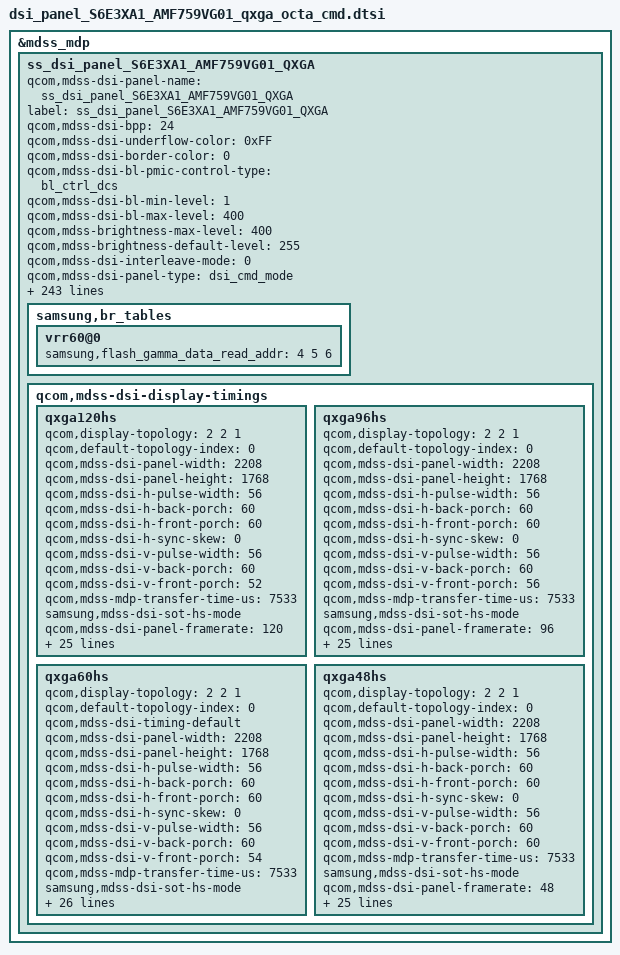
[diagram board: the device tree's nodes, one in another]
/* Copyright (c) 2012, Samsung Electronics Corporation. All rights reserved.
 *
 * This program is free software; you can redistribute it and/or modify
 * it under the terms of the GNU General Public License version 2 and
 * only version 2 as published by the Free Software Foundation.
 *
 * This program is distributed in the hope that it will be useful,
 * but WITHOUT ANY WARRANTY; without even the implied warranty of
 * MERCHANTABILITY or FITNESS FOR A PARTICULAR PURPOSE.  See the
 * GNU General Public License for more details.
 */

&mdss_mdp {
	ss_dsi_panel_S6E3XA1_AMF759VG01_QXGA: ss_dsi_panel_S6E3XA1_AMF759VG01_QXGA {
		qcom,mdss-dsi-panel-name = "ss_dsi_panel_S6E3XA1_AMF759VG01_QXGA";
		label = "ss_dsi_panel_S6E3XA1_AMF759VG01_QXGA";

		qcom,mdss-dsi-bpp = <24>;

		qcom,mdss-dsi-underflow-color = <0xFF>;
		qcom,mdss-dsi-border-color = <0>;

		qcom,mdss-dsi-bl-pmic-control-type = "bl_ctrl_dcs";

		qcom,mdss-dsi-bl-min-level = <1>;
		qcom,mdss-dsi-bl-max-level = <400>;
		qcom,mdss-brightness-max-level = <400>;
		qcom,mdss-brightness-default-level = <255>;
		qcom,mdss-dsi-interleave-mode = <0>;
		qcom,mdss-dsi-panel-type = "dsi_cmd_mode";

		qcom,mdss-dsi-te-pin-select = <1>;

		qcom,dynamic-mode-switch-enabled;
		qcom,dynamic-mode-switch-type = "dynamic-resolution-switch-immediate";

		qcom,mdss-dsi-te-dcs-command = <1>;
		qcom,mdss-dsi-wr-mem-start = <0x2C>;
		qcom,mdss-dsi-wr-mem-continue = <0x3C>;

		qcom,mdss-dsi-pixel-packing = "loose";

		qcom,mdss-dsi-virtual-channel-id = <0>;
		qcom,mdss-dsi-color-order = "rgb_swap_rgb";
		qcom,mdss-dsi-lane-0-state;
		qcom,mdss-dsi-lane-1-state;
		qcom,mdss-dsi-lane-2-state;
		qcom,mdss-dsi-lane-3-state;

		qcom,mdss-dsi-t-clk-pre = <0x24>;
		qcom,mdss-dsi-t-clk-post = <0x1b>;

		qcom,mdss-dsi-mdp-trigger = "none";
		qcom,mdss-dsi-dma-trigger = "trigger_sw";

		qcom,mdss-pan-physical-height-dimension = <120>; /* 120.472 */
		qcom,mdss-pan-physical-width-dimension = <150>; /* 150.453 */

		qcom,mdss-dsi-reset-sequence = <0 1>, <1 5>;

		/*qcom,mdss-dsi-lp11-init;*/
		/*qcom,mdss-dsi-init-delay-us = <1000>;*/

		qcom,mdss-dsi-rx-eot-ignore;
		qcom,mdss-dsi-tx-eot-append;

		/* HDR Setting */
		qcom,mdss-dsi-panel-hdr-enabled;
		qcom,mdss-dsi-panel-hdr-color-primaries = <15635 16450 34000 16000 13250 34500 7500 3000>;
		qcom,mdss-dsi-panel-peak-brightness = <4000000>;
		qcom,mdss-dsi-panel-average-brightness = <1200000>;
		qcom,mdss-dsi-panel-blackness-level = <5>;

		qcom,ulps-enabled;
		/* qcom,suspend-ulps-enabled; */
		qcom,esd-check-enabled;
		qcom,mdss-dsi-panel-status-check-mode ="irq_check";
		/*qcom,mdss-dsi-panel-status-read-length;*/
		/*qcom,mdss-dsi-panel-status-value;*/
		/*qcom,mdss-dsi-panel-status-irq-trigger1 = "rising";*/
		//qcom,mdss-dsi-panel-status-irq-trigger1 = "falling";

		/* *************************************************************
		 * Below  parameters are samsung dependent thigs
		 * *************************************************************
		 */
		samsung,panel-vendor = "SDC";
		samsung,disp-model = "AMF759VG01";
		samsung,panel-lpm-enable;
		samsung,support_irc;
		samsung,elvss_interpolation_temperature = <(-15)>;
		samsung,support_factory_panel_swap;
		samsung,support_gct;
		samsung,esc-clk-128M;
		samsung,support_gamma_mode2;
		samsung,support_gpara;

		/* *************************************************************
		 * TEST MODE
		 * **************************************************************
		 */


		/***************************** 60 NM *****************************/
		/* MCD Test : 60hz Normal mode */
		samsung,mcd_on_tx_cmds_revA = [
			29 00 00 00 00 00 03 F0 5A 5A	/* TEST KEY2 Enable */
			29 01 00 00 00 00 EC CB			/* LTPS Setting */
				00 25 1D 1D 00 00 00 00 00 DF 4F DD E5 D2 E3 9A
				90 D9 D0 C7 D0 C2 D0 88 D0 C3 50 DF CF DD E5 D2
				E3 9A 90 D9 D0 87 D0 82 D0 C8 D0 C3 D0 80 C0 00
				00 00 00 00 00 00 00 00 00 00 00 00 00 00 00 00
				00 00 00 00 00 00 04 00 06 00 00 00 0B 00 02 00
				06 02 00 00 00 00 00 00 00 00 00 00 00 00 50 2E
				1A 00 00 00 40 2E 1A 00 00 00 00 00 00 00 00 00
				00 00 00 00 00 00 00 00 00 00 00 00 04 00 00 00
				00 00 33 00 00 00 00 00 00 50 04 37 40 04 37 00
				00 00 00 00 00 F8 04 37 00 00 00 D8 04 37 00 00
				00 00 00 00 00 00 00 12 00 00 00 00 00 00 00 00
				04 00 06 00 00 00 0B 00 02 00 06 02 00 00 00 00
				00 00 00 00 00 00 00 00 50 0B 35 00 00 00 40 0B
				35 00 00 00 00 00 00 00 00 00 00 00 00 00 00 00
				00 00 00 00 00 00 04 00 00 00 00
			29 00 00 00 00 00 03 B0 13 F6
			29 00 00 00 00 00 02 F6 00
			29 01 00 00 64 00 02 F7 0F	/* gamma update, delay 100ms */
			29 01 00 00 00 00 03 F0 A5 A5	/* TEST KEY2 Disable */
		];

		samsung,mcd_off_tx_cmds_revA = [
			29 00 00 00 00 00 03 F0 5A 5A	/* TEST KEY2 Enable */
			29 01 00 00 00 00 EC CB			/* LTPS Setting */
				00 25 1D 1D 00 00 00 00 00 DF 0F DD E5 D2 E3 9A
				90 D9 D0 C7 D0 C2 D0 88 D0 C3 50 DF CF DD E5 D2
				E3 9A 90 D9 D0 87 D0 82 D0 C8 D0 C3 D0 80 C0 00
				00 00 00 00 00 00 00 00 00 00 00 00 00 00 00 00
				00 00 00 00 00 00 04 00 06 00 00 00 0B 00 02 00
				06 02 00 00 00 00 00 00 00 00 00 00 00 00 50 2E
				1A 00 00 00 40 2E 1A 00 00 00 00 00 00 00 00 00
				00 00 00 00 00 00 00 00 00 00 00 00 04 00 00 00
				00 00 33 00 00 00 00 00 00 50 04 37 40 04 37 00
				00 00 00 00 00 F8 04 37 00 00 00 D8 04 37 00 00
				00 00 00 00 00 00 00 00 00 00 00 00 00 00 00 00
				04 00 06 00 00 00 0B 00 02 00 06 02 00 00 00 00
				00 00 00 00 00 00 00 00 50 0B 35 00 00 00 40 0B
				35 00 00 00 00 00 00 00 00 00 00 00 00 00 00 00
				00 00 00 00 00 00 04 00 00 00 00
			29 00 00 00 00 00 03 B0 13 F6
			29 00 00 00 00 00 02 F6 46
			29 00 00 00 64 00 02 F7 0F	/* gamma update, delay 100ms */
			29 01 00 00 00 00 03 F0 A5 A5	/* TEST KEY2 Disable */
		];
		/* MCD Test : 120hz Normal mode */
		samsung,mcd_on_tx_cmds_revC = [
			29 00 00 00 00 00 03 F0 5A 5A	/* TEST KEY2 Enable */
			29 00 00 00 00 00 03 FC 5A 5A	/* TEST KEY1 Enable */
			29 00 00 00 00 00 02 C5 08		/* FFC Disable */
			29 00 00 00 00 00 02 BD 00		/* LFD Disable */
			29 00 00 00 00 00 03 B0 23 F6
			29 00 00 00 00 00 02 F6 24
			29 01 00 00 00 00 EC CB			/* LTPS Setting */
				00 25 1D 1D 00 00 00 00 00 DF 0F DD E5 D2 E3 9A
				90 D9 D0 C7 D0 C2 D0 88 D0 C3 50 DF CF DD E5 D2
				E3 9A 90 D9 D0 87 D0 82 D0 C8 D0 C3 D0 80 C0 00
				00 00 00 00 00 00 00 00 00 00 00 00 00 00 00 00
				00 00 00 00 00 00 04 00 08 00 00 00 0F 00 02 00
				00 00 00 00 00 00 00 00 00 00 00 00 00 00 50 2E
				1A 00 00 00 40 2E 1A 00 00 00 00 00 00 00 00 00
				00 00 00 00 00 00 00 00 00 00 00 00 04 00 00 00
				00 00 33 00 00 00 00 00 00 50 04 37 40 04 37 00
				00 00 00 00 00 F8 04 37 00 00 00 D8 04 37 00 00
				00 00 00 00 00 00 00 04 00 00 00 00 00 00 00 00
				04 00 08 00 00 00 0F 00 02 00 00 00 00 00 00 00
				00 00 00 00 00 00 00 00 50 5C 35 00 00 00 40 5C
				35 00 00 00 00 00 00 00 00 00 00 00 00 00 00 00
				00 00 00 00 00 00 04 00 00 00 00
			29 01 00 00 00 00 E4 B7			/* LTPS Setting */
				00 33 00 00 00 00 00 00 50 09 6E 40 09 6E 00 00
				00 00 00 00 F8 09 6E 00 00 00 D8 09 6E 00 00 00
				00 00 00 00 00 00 24 00 00 00 00 00 00 00 00 04
				00 08 00 00 00 0F 00 02 00 00 00 00 00 00 00 00
				00 00 00 00 00 00 00 50 40 0D 00 00 00 40 40 0D
				00 00 00 00 00 00 00 00 00 00 00 00 00 00 00 00
				00 00 00 00 00 04 00 00 00 00 00 33 00 00 00 00
				00 00 50 02 44 40 02 44 00 00 00 00 00 00 F8 02
				44 00 00 00 D8 02 44 00 00 00 00 00 00 00 00 00
				10 00 00 00 00 00 00 00 00 00 00 00 00 00 00 00
				00 00 00 00 00 00 00 00 00 00 00 00 00 00 00 00
				00 00 00 00 00 00 00 00 00 00 00 00 00 00 00 00
				00 00 00 00 00 00 00 00 00 00 00 00 00 00 00 00
				00 00 00 00 00 00 00 00 00 00 00 00 00 00 00 00
				00 00 00
			29 00 00 00 00 00 03 B0 08 F2
			29 00 00 00 00 00 03 F2 28 50
			29 00 00 00 00 00 03 B0 0F F2
			29 00 00 00 00 00 03 F2 28 50
			29 00 00 00 00 00 03 B0 17 F6
			29 00 00 00 00 00 02 F6 00
			29 01 00 00 64 00 02 F7 0F	/* gamma update, delay 100ms */
			29 00 00 00 00 00 03 FC A5 A5	/* TEST KEY1 Disable */
			29 01 00 00 00 00 03 F0 A5 A5	/* TEST KEY2 Disable */
		];

		samsung,mcd_off_tx_cmds_revC = [
			29 00 00 00 00 00 03 F0 5A 5A	/* TEST KEY2 Enable */
			29 00 00 00 00 00 03 FC 5A 5A	/* TEST KEY1 Enable */
			29 00 00 00 00 00 02 C5 0D		/* FFC Disable */
			29 00 00 00 00 00 03 B0 23 F6
			29 00 00 00 00 00 02 F6 00
			29 01 00 00 00 00 EC CB			/* LTPS Setting */
				00 25 1D 1D 00 00 00 00 00 DF 0F DD E5 D2 E3 9A
				90 D9 D0 C7 D0 C2 D0 88 D0 C3 50 DF CF DD E5 D2
				E3 9A 90 D9 D0 87 D0 82 D0 C8 D0 C3 D0 80 C0 00
				00 00 00 00 00 00 00 00 00 00 00 00 00 00 00 00
				00 00 00 00 00 00 04 00 08 00 00 00 0F 00 02 00
				06 02 00 00 00 00 00 00 00 00 00 00 00 00 50 2E
				1A 00 00 00 40 2E 1A 00 00 00 00 00 00 00 00 00
				00 00 00 00 00 00 00 00 00 00 00 00 04 00 00 00
				00 00 1D 00 00 00 00 00 00 50 04 37 40 04 37 00
				00 00 00 00 00 F8 04 37 00 00 00 D8 04 37 00 00
				00 00 00 00 00 00 00 00 00 00 00 00 00 00 00 00
				04 00 08 00 00 00 0F 00 02 00 06 02 00 00 00 00
				00 00 00 00 00 00 00 00 50 0B 35 00 00 00 40 0B
				35 00 00 00 00 00 00 00 00 00 00 00 00 00 00 00
				00 00 00 00 00 00 04 00 00 00 00
			29 01 00 00 00 00 E4 B7			/* LTPS Setting */
				00 1D 00 00 00 00 00 00 50 09 37 40 09 37 00 00
				00 00 00 00 F8 09 2E 00 00 00 D8 09 2E 00 00 00
				00 00 00 00 00 00 00 00 00 00 00 00 00 00 00 04
				00 08 00 00 00 0F 00 02 00 00 00 00 00 00 00 00
				00 00 00 00 00 00 00 50 30 0D 00 00 00 40 30 0D
				00 00 00 00 00 00 00 00 00 00 00 00 00 00 00 00
				00 00 00 00 00 04 00 00 00 00 00 1D 00 00 00 00
				00 00 50 02 44 40 02 44 00 00 00 00 00 00 F8 02
				44 00 00 00 D8 02 44 00 00 00 00 00 00 00 00 00
				00 00 00 00 00 00 00 00 00 00 00 00 00 00 00 00
				00 00 00 00 00 00 00 00 00 00 00 00 00 00 00 00
				00 00 00 00 00 00 00 00 00 00 00 00 00 00 00 00
				00 00 00 00 00 00 00 00 00 00 00 00 00 00 00 00
				00 00 00 00 00 00 00 00 00 00 00 00 00 00 00 00
				00 00 00
			29 00 00 00 00 00 03 B0 08 F2
			29 00 00 00 00 00 03 F2 14 50
			29 00 00 00 00 00 03 B0 0F F2
			29 00 00 00 00 00 03 F2 14 50
			29 00 00 00 00 00 03 B0 17 F6
			29 00 00 00 00 00 02 F6 3D
			29 00 00 00 00 00 02 F7 0F		/* gamma update */
			29 00 00 00 00 00 02 BD 01		/* LFD Enable */
			29 00 00 00 00 00 03 FC A5 A5	/* TEST KEY1 Disable */
			29 01 00 00 00 00 03 F0 A5 A5	/* TEST KEY2 Disable */
		];

		/* BRIGHTDOT Test : 120hz HS mode */
		samsung,brightdot_on_tx_cmds_revA = [
			29 00 00 00 00 00 03 F0 5A 5A	/* TEST KEY2 Enable */
			29 00 00 00 00 00 03 51 03 FF	/* max brightness */
			29 00 00 00 00 00 03 B0 59 B1
			29 00 00 00 00 00 03 B1 07 00	/* AOR 100% */
			29 01 00 00 64 00 02 F7 0F	/* gamma update */
			29 00 00 00 00 00 03 F0 A5 A5	/* TEST KEY2 Disable */
		];

		samsung,brightdot_off_tx_cmds_revA = [
			29 00 00 00 00 00 03 F0 5A 5A	/* TEST KEY2 Enable */
			29 00 00 00 00 00 03 B0 59 B1
			29 00 00 00 00 00 03 B1 01 20	/* AOR 16% (OTP value) */
			29 01 00 00 64 00 02 F7 0F	/* gamma update */
			29 00 00 00 00 00 03 F0 A5 A5	/* TEST KEY2 Disable */
		];

		samsung,brightdot_lf_on_tx_cmds_revA = [
			29 00 00 00 00 00 03 F0 5A 5A	/* TEST KEY2 Enable */
			29 00 00 00 00 00 03 51 03 FF	/* max brightness */
			29 00 00 00 00 00 03 B0 0C BD
			29 00 00 00 00 00 03 BD 00 EF	/* LFD min freq. = 0.5hz on 120HS mdoe */
			29 00 00 00 00 00 03 60 00 EF	/* LFD max freq. = 0.5hz on 120HS mdoe */
			29 01 00 00 64 00 02 F7 0F	/* gamma update */
			29 00 00 00 00 00 03 F0 A5 A5	/* TEST KEY2 Disable */
		];

		/* samsung,brightdot_lf_off_tx_cmds_revA = []; by updating brightness, LFD will be recovered */

		/* Gray Spot Test : 120Hz HS mode */
		samsung,gray_spot_test_on_tx_cmds_revA = [
			29 00 00 00 00 00 03 F0 5A 5A	/* TEST KEY2 Enable */
			29 00 00 00 00 00 02 BD 00		/* LFD Disable */
			29 00 00 00 00 00 03 B0 02 B5
			29 00 00 00 00 00 02 B5 23
			29 00 00 00 00 00 03 B0 4A B5
			29 00 00 00 00 00 02 B5 12
			29 01 00 00 14 00 02 F7 0F	/* gamma update delay 20ms*/
			29 00 00 00 00 00 03 B0 17 F6
			29 00 00 00 00 00 02 F6 00
			29 00 00 00 00 00 03 B0 01 F2
			29 00 00 00 00 00 04 F2 00 BA 00
			29 00 00 00 00 00 02 F7 0F	/* gamma update */
			29 01 00 00 00 00 03 F0 A5 A5	/* TEST KEY2 Disable */
		];

		samsung,gray_spot_test_off_tx_cmds_revA = [
			29 00 00 00 00 00 03 F0 5A 5A	/* TEST KEY2 Enable */
			29 00 00 00 00 00 03 B0 17 F6
			29 00 00 00 00 00 02 F6 3D
			29 00 00 00 00 00 03 B0 01 F2
			29 00 00 00 00 00 04 F2 14 BA 40
			29 00 00 00 00 00 03 B0 02 B5
			29 00 00 00 00 00 02 B5 16
			29 00 00 00 00 00 03 B0 4A B5
			29 00 00 00 00 00 02 B5 00
			29 00 00 00 00 00 02 BD 01		/* LFD Enable */
			29 00 00 00 00 00 02 F7 0F	/* gamma update */
			29 01 00 00 00 00 03 F0 A5 A5	/* TEST KEY2 Disable */
		];

		samsung,gray_spot_rx_cmds_revA= [06 01 00 00 00 00 01 B5 01 74];

		/* Micro Crack Test 120Hz HS*/
		samsung,micro_short_test_on_tx_cmds_revA = [
			29 00 00 00 00 00 03 F0 5A 5A
			29 00 00 00 00 00 03 B0 17 F6
			29 00 00 00 00 00 02 F6 2B
			29 00 00 00 00 00 03 BF 33 25
			29 01 00 00 00 00 03 F0 A5 A5
		];

		samsung,micro_short_test_off_tx_cmds_revA = [
			29 00 00 00 00 00 03 F0 5A 5A
			29 00 00 00 00 00 03 B0 17 F6
			29 00 00 00 00 00 02 F6 3D
			29 00 00 00 00 00 03 BF 00 07
			29 01 00 00 00 00 03 F0 A5 A5
		];

		samsung,ccd_test_on_tx_cmds_revA = [
			29 00 00 00 00 00 03 F0 5A 5A
			29 00 00 00 00 00 03 B0 02 CC
			29 01 00 00 00 00 02 CC 01
			29 00 00 00 00 00 03 F0 A5 A5
		];

		samsung,ccd_state_rx_cmds_revA= [06 01 00 00 00 00 01 CD 01 00];

		samsung,ccd_pass_val = <0x00>;	/* pass */
		samsung,ccd_fail_val = <0x04>;	/* chip crack */

		samsung,ccd_test_off_tx_cmds_revA = [
			29 00 00 00 00 00 03 F0 5A 5A
			29 00 00 00 00 00 03 B0 02 CC			
			29 00 00 00 00 00 02 CC 00
			29 01 00 00 00 00 03 F0 A5 A5
		];

		samsung,gct_checksum_rx_cmds_revA = [06 01 00 00 00 00 01 AF 01 00];

		samsung,gct_enter_tx_cmds_revA = [
			29 00 00 00 00 00 03 9F A5 A5	// TEST KEY Enable
			05 01 00 00 78 00 01 01		// S/W Reset, Delay 120ms

			29 00 00 00 00 00 03 F0 5A 5A	// TEST KEY Enable
			29 00 00 00 00 00 03 FC 5A 5A	// TEST KEY Enable

			29 00 00 00 00 00 03 B0 0A FE	// Global Para

			29 00 00 00 00 00 02 FE 14	// Para

			29 00 00 00 00 00 5A 9E		/* PPS */
				11 00 00 89 30 80 06 E8
				08 A0 00 22 04 50 04 50
				02 00 03 28 00 20 04 6C
				00 0F 00 0C 02 E9 01 77
				18 00 10 F0 03 0C 20 00
				06 0B 0B 33 0E 1C 2A 38
				46 54 62 69 70 77 79 7B
				7D 7E 01 02 01 00 09 40
				09 BE 19 FC 19 FA 19 F8
				1A 38 1A 78 1A B6 2A F6
				2B 34 2B 74 3B 74 6B F4
				00

			05 01 00 00 0A 00 01 11		// Sleep out, Delay 10ms

			29 00 00 00 00 00 03 B0 2D FE
			29 01 00 00 32 00 02 FE 7A
			29 00 00 00 00 00 03 51 03 FF
			29 01 00 00 00 00 02 53 20
			29 01 00 00 00 00 02 9D 01		/* DSC enable */
			29 01 00 00 32 00 02 D7 04		/* LDDM LV Setting */
			29 01 00 00 00 00 02 2C 00		/* Checksum start */

			29 01 00 00 14 00 02 BE 05		/* GDBIST Pattern 5A , delay 20ms */
			29 01 00 00 14 00 02 BE 00		/* GDBIST Disable, delay 20ms */
			29 00 00 00 00 00 02 BE 07		/* GDBIST Pattern A5 , delay 150ms(panel file) */

			/* checksum read */
		];

		samsung,gct_mid_tx_cmds_revA = [
			29 01 00 00 14 00 02 BE 00		// GDBIST Disable, delay 20ms
			29 00 00 00 00 00 02 BE 05		// GDBIST Pattern 2 , delay 150ms(panel file)

			/* checksum read */
		];

		samsung,gct_exit_tx_cmds_revA = [
			29 00 00 00 00 00 02 BE 00		// GDBIST Disable
			29 00 00 00 00 00 02 D7 00		// VDDM Normal Setting (VDDM 0x0: 1.0V, 0x10: 0.9V, 0x30: 1.1V)
			29 00 00 00 00 00 03 9F 5A 5A	// TEST Key Disable
			29 00 00 00 00 00 03 F0 A5 A5	// TEST Key Disable
			29 01 00 00 00 00 03 FC A5 A5	// TEST Key Disable
		];

		/* *************************************************************
		 *  SELF DISPLAY
		 * *************************************************************
		 */
		samsung,support_self_display;
		ss,self_display = <&self_display_XA1_dtsi>;


		/* Self idle-Display Operation (Enable/Disable) */
		samsung,self_idle_aod_enter = [
			29 00 00 00 00 00 03 FC 5A 5A	/* TEST KEY Enable */
			29 00 00 00 00 00 05 76 13 0C 00 11
			29 00 00 00 00 00 03 FC A5 A5	/* TEST KEY Disable */
		];

		samsung,self_idle_aod_exit = [
			29 00 00 00 00 00 03 FC 5A 5A	/* TEST KEY Enable */
			29 00 00 00 00 00 05 76 13 0C 00 00
			29 00 00 00 00 00 02 75 01
			29 00 00 00 00 00 03 FC A5 A5	/* TEST KEY Disable */
		];

		/* Self idle-Display Operation (SELF TIME UPDATE) */
		samsung,self_idle_timer_on = [
			29 00 00 00 00 00 03 F0 5A 5A	/* TEST KEY Enable */
			29 00 00 00 00 00 0B 81
								00 03 00 00 00
								00 03 00 00 00
			29 00 00 00 00 00 03 F0 A5 A5	/* TEST KEY Disable */
		];

		samsung,self_idle_timer_off = [
			29 00 00 00 00 00 03 F0 5A 5A	/* TEST KEY Enable */
			29 00 00 00 00 00 03 81 00 00
			29 01 00 00 11 00 03 F0 A5 A5	/* TEST KEY Disable + Delay 16.7 ms*/
		];

		/* Self idle-Display Operation (SELF MOVE) */

		samsung,self_idle_move_on_pattern1 = [
			29 00 00 00 00 00 03 F0 5A 5A	/* TEST KEY Enable */
			29 00 00 00 00 00 23 7D
						10 01 02 00 00
						10 01 50 05 10 01 50 05
						10 01 50 05 10 01 50 05
						10 01 00 00 00 00 00 00
						00 00 00 00 00
			29 00 00 00 00 00 03 F0 A5 A5	/* TEST KEY Disable */
		];

		samsung,self_idle_move_on_pattern2 = [
			29 00 00 00 00 00 03 F0 5A 5A	/* TEST KEY Enable */
			29 00 00 00 00 00 23 7D
						10 01 02 00 00
						10 01 50 05 10 01 50 05
						10 01 50 05 10 01 50 05
						10 01 00 00 00 00 00 00
						00 00 00 00 00
			29 00 00 00 00 00 03 F0 A5 A5	/* TEST KEY Disable */
		];

		samsung,self_idle_move_on_pattern3 = [
			29 00 00 00 00 00 03 F0 5A 5A	/* TEST KEY Enable */
			29 00 00 00 00 00 23 7D
								10 01 02 00 00
								10 01 50 05 10 01 50 05
								10 01 50 05 10 01 50 05
								10 01 00 00 00 00 00 00
								00 00 00 00 00
			29 00 00 00 00 00 03 F0 A5 A5	/* TEST KEY Disable */
		];
		samsung,self_idle_move_on_pattern4 = [
			29 00 00 00 00 00 03 F0 5A 5A	/* TEST KEY Enable */
			29 00 00 00 00 00 23 7D
								10 01 02 00 00
								10 01 50 05 10 01 50 05
								10 01 50 05 10 01 50 05
								10 01 00 00 00 00 00 00
								00 00 00 00 00
			29 00 00 00 00 00 03 F0 A5 A5	/* TEST KEY Disable */
		];
		samsung,self_idle_move_off = [
			29 00 00 00 00 00 03 F0 5A 5A	/* TEST KEY Enable */
			29 00 00 00 00 00 03 7D 00 00
			29 00 00 00 00 00 03 F0 A5 A5	/* TEST KEY Disable */
		];

		/*
		*************************************************************************************************************************
		* Self mask check debug (SELF MASK CHECK)
		*************************************************************************************************************************
		*/

		samsung,mask_crc_pass_data = [2A C3];

		/* *************************************************************
		 *  mAFPC
		 * *************************************************************
		 */
		samsung,support_mafpc;
		ss,mafpc = <&ss_mafpc_XA1_dtsi>;
		samsung,mafpc_crc_pass_data = [62 2D];

		/* *************************************************************
		 *  Tx
		 * *************************************************************
		 */
		samsung,level0_key_enable_tx_cmds_revA	= [29 01 00 00 00 00 03 9F A5 A5]; /* PASSWD0 */
		samsung,level0_key_disable_tx_cmds_revA	= [29 01 00 00 00 00 03 9F 5A 5A]; /* PASSWD0 */
		samsung,level1_key_enable_tx_cmds_revA	= [29 01 00 00 00 00 03 F0 5A 5A]; /* PASSWD1 */
		samsung,level1_key_disable_tx_cmds_revA	= [29 01 00 00 00 00 03 F0 A5 A5]; /* PASSWD1 */
		samsung,level2_key_enable_tx_cmds_revA	= [29 01 00 00 00 00 03 FC 5A 5A];
		samsung,level2_key_disable_tx_cmds_revA	= [29 01 00 00 00 00 03 FC A5 A5];

		/* BRIGHTNESS_MAX_PACKET = 100 */
		samsung,brightness_tx_cmds_revA = [
			39 01 00 00 00 00 01 00
			39 01 00 00 00 00 01 00
			39 01 00 00 00 00 01 00
			39 01 00 00 00 00 01 00
			39 01 00 00 00 00 01 00
			39 01 00 00 00 00 01 00
			39 01 00 00 00 00 01 00
			39 01 00 00 00 00 01 00
			39 01 00 00 00 00 01 00
			39 01 00 00 00 00 01 00
			39 01 00 00 00 00 01 00
			39 01 00 00 00 00 01 00
			39 01 00 00 00 00 01 00
			39 01 00 00 00 00 01 00
			39 01 00 00 00 00 01 00
			39 01 00 00 00 00 01 00
			39 01 00 00 00 00 01 00
			39 01 00 00 00 00 01 00
			39 01 00 00 00 00 01 00
			39 01 00 00 00 00 01 00
			39 01 00 00 00 00 01 00
			39 01 00 00 00 00 01 00
			39 01 00 00 00 00 01 00
			39 01 00 00 00 00 01 00
			39 01 00 00 00 00 01 00
			39 01 00 00 00 00 01 00
			39 01 00 00 00 00 01 00
			39 01 00 00 00 00 01 00
			39 01 00 00 00 00 01 00
			39 01 00 00 00 00 01 00
			39 01 00 00 00 00 01 00
			39 01 00 00 00 00 01 00
			39 01 00 00 00 00 01 00
			39 01 00 00 00 00 01 00
			39 01 00 00 00 00 01 00
			39 01 00 00 00 00 01 00
			39 01 00 00 00 00 01 00
			39 01 00 00 00 00 01 00
			39 01 00 00 00 00 01 00
			39 01 00 00 00 00 01 00
			39 01 00 00 00 00 01 00
			39 01 00 00 00 00 01 00
			39 01 00 00 00 00 01 00
			39 01 00 00 00 00 01 00
			39 01 00 00 00 00 01 00
			39 01 00 00 00 00 01 00
			39 01 00 00 00 00 01 00
			39 01 00 00 00 00 01 00
			39 01 00 00 00 00 01 00
			39 01 00 00 00 00 01 00
			39 01 00 00 00 00 01 00
			39 01 00 00 00 00 01 00
			39 01 00 00 00 00 01 00
			39 01 00 00 00 00 01 00
			39 01 00 00 00 00 01 00
			39 01 00 00 00 00 01 00
			39 01 00 00 00 00 01 00
			39 01 00 00 00 00 01 00
			39 01 00 00 00 00 01 00
			39 01 00 00 00 00 01 00
			39 01 00 00 00 00 01 00
			39 01 00 00 00 00 01 00
			39 01 00 00 00 00 01 00
			39 01 00 00 00 00 01 00
			39 01 00 00 00 00 01 00
			39 01 00 00 00 00 01 00
			39 01 00 00 00 00 01 00
			39 01 00 00 00 00 01 00
			39 01 00 00 00 00 01 00
			39 01 00 00 00 00 01 00
			39 01 00 00 00 00 01 00
			39 01 00 00 00 00 01 00
			39 01 00 00 00 00 01 00
			39 01 00 00 00 00 01 00
			39 01 00 00 00 00 01 00
			39 01 00 00 00 00 01 00
			39 01 00 00 00 00 01 00
			39 01 00 00 00 00 01 00
			39 01 00 00 00 00 01 00
			39 01 00 00 00 00 01 00
			39 01 00 00 00 00 01 00
			39 01 00 00 00 00 01 00
			39 01 00 00 00 00 01 00
			39 01 00 00 00 00 01 00
			39 01 00 00 00 00 01 00
			39 01 00 00 00 00 01 00
			39 01 00 00 00 00 01 00
			39 01 00 00 00 00 01 00
			39 01 00 00 00 00 01 00
			39 01 00 00 00 00 01 00
			39 01 00 00 00 00 01 00
			39 01 00 00 00 00 01 00
			39 01 00 00 00 00 01 00
			39 01 00 00 00 00 01 00
			39 01 00 00 00 00 01 00
			39 01 00 00 00 00 01 00
			39 01 00 00 00 00 01 00
			39 01 00 00 00 00 01 00
			39 01 00 00 00 00 01 00
			39 01 00 00 00 00 01 00
		];

		/* use poinging gpara (long write) */
		samsung,reg_read_pos_tx_cmds_revA = [
			29 00 00 00 00 00 03 B0 00 00
		];

		samsung,display_on_tx_cmds_revA = [
			29 01 00 00 00 00 03 9F A5 A5		/* LV1 (9F) unlock */
			05 01 00 00 00 00 01 29
			29 01 00 00 00 00 03 9F 5A 5A		/* LV1 (9F) lock */
		];

		samsung,display_off_tx_cmds_revA = [05 01 00 00 00 00 02 28 00];

		/* *************************************************************
		 *  Rx (Module Information READ)
		 * *************************************************************
		 */
		samsung,mdnie_read_rx_cmds_revA		= [06 01 00 00 00 00 01 D8 04 03]; /* White color position */
		samsung,manufacture_date_rx_cmds_revA	= [06 01 00 00 00 00 01 D8 04 07]; /* manufacture data 4 byte*/
		samsung,octa_id_rx_cmds_revA		= [06 01 00 00 00 00 01 D8 14 0E]; /* manufacture information */
		samsung,cell_id_rx_cmds_revA		= [06 01 00 00 00 00 01 D8 07 07]; /* manufacture data 7 byte*/
		samsung,ddi_id_rx_cmds_revA		= [06 01 00 00 00 00 01 D6 05 00];	/* CHIP ID */


		samsung,manufacture_id0_rx_cmds_revA	= [06 01 00 00 00 00 01 da 01 00];
		samsung,manufacture_id1_rx_cmds_revA	= [06 01 00 00 00 00 01 db 01 00];
		samsung,manufacture_id2_rx_cmds_revA	= [06 01 00 00 00 00 01 dc 01 00];

		samsung,ldi_debug0_rx_cmds_revA		= [06 01 00 00 00 00 01 0A 01 00]; /* rddpm */
		//samsung,ldi_debug1_rx_cmds_revA		= [06 01 00 00 00 00 01 0E 01 00]; /* no operation */
		//samsung,ldi_debug2_rx_cmds_revA		= [06 01 00 00 00 00 01 0E 01 00]; /* errfg */
		//samsung,ldi_debug3_rx_cmds_revA		= [06 01 00 00 00 00 01 0E 01 00]; /* rddsm*/
		//samsung,ldi_debug4_rx_cmds_revA		= [06 01 00 00 00 00 01 05 01 00]; /* dsierr */
		//samsung,ldi_debug5_rx_cmds_revA		= [06 01 00 00 00 00 01 0F 01 00]; /* self_diag*/

		/* 255 bytes, its ddi max size is 512, and sw limit is 0xff = 255... */
		//samsung,ldi_debug_logbuf_rx_cmds_revA	= [06 01 00 00 00 00 01 9C FF 00];

		samsung,mtp_read_sysfs_rx_cmds_revA	= [06 01 00 00 00 00 01 00 00 00];

		samsung,mtp_write_sysfs_tx_cmds_revA	= [
			29 00 00 00 00 00 3D 00
						00 00 00 00 00 00 00 00 00 00
						00 00 00 00 00 00 00 00 00 00
						00 00 00 00 00 00 00 00 00 00
						00 00 00 00 00 00 00 00 00 00
						00 00 00 00 00 00 00 00 00 00
						00 00 00 00 00 00 00 00 00 00
		];

		samsung,smart_dimming_mtp_rx_cmds_revA	= [06 01 00 00 00 00 01 c9 DE 00]; /* C8h 0x00~0xDD: 222 bytes for 48/96hz gamma compensation */

		/* *************************************************************
		 *  COPR
		 * *************************************************************
		 */
		samsung,copr_enable_tx_cmds_revA = [
			29 00 00 00 00 00 03 F0 5A 5A
			29 00 00 00 00 00 35 E1
				09 15 15 00 00 00 00 00
				00 00 03 1F 00 2F 02 53
				00 5F 02 83 08 1F 05 B1
				08 4F 05 E1 00 00 00 00
				08 9F 06 E7 00 00 00 00
				08 9F 06 E7 00 00 00 00 08 9F 06 E7
			29 01 00 00 00 00 03 F0 A5 A5
		];

		samsung,copr_disable_tx_cmds_revA = [
			29 00 00 00 00 00 03 F0 5A 5A
			29 00 00 00 00 00 02 E1 00
			29 01 00 00 00 00 03 F0 A5 A5
		];

		/* *************************************************************
		 *  SELF DISPLAY
		 * *************************************************************
		 */

		/* *************************************************************
		 * ACL command list and mappings
		 * **************************************************************
		 */

		samsung,acl_on_tx_cmds_revA = [
			/*
			* B4 Register Setting Guide
			* 2nd (16 Frame Avg at ACL Off) : 44
			* 3rd~4th (start point 50%) : 40 FF
			* 6th (ACL 8) : 0x26 ℃ ACL 8%
			*/
			29 01 00 00 00 00 07 B4 00 55 40 FF 26 50
			29 00 00 00 00 00 03 B0 0F B4
			29 00 00 00 00 00 02 B4 00
			29 01 00 00 00 00 02 55 02	/* ACL ON */
		];

		samsung,acl_off_tx_cmds_revA = [
			29 01 00 00 00 00 03 B4 00 44
			29 01 00 00 00 00 02 55 00	/* ACL OFF */
		];

		/* *************************************************************
		 * Dynamic MIPI Clock
		 * **************************************************************
		 */
		samsung,support_dynamic_mipi_clk;

		samsung,ffc_tx_cmds_revA = [
			29 00 00 00 00 00 03 FC 5A 5A			/* TEST KEY3 Enable*/
			29 00 00 00 00 00 08 C5 0D 00 C8 29 0F 29 0F	/* Default 1362 Mbps */
			29 00 00 00 00 00 03 FC A5 A5			/* TEST KEY3 Disable*/
		];

		samsung,dyn_mipi_clk_ffc_cmds_revA = [
			29 00 00 00 00 00 08 C5 0D 00 C8 29 0F 29 0F	/* 0. Default 1362 Mbps */
			29 00 00 00 00 00 08 C5 0D 00 C8 28 E1 28 E1	/* 1. 1368 Mbps */
			29 00 00 00 00 00 08 C5 0D 00 C8 29 0F 29 0F	/* 2. 1362 Mbps */
			29 00 00 00 00 00 08 C5 0D 00 C8 2A 1C 2A 1C	/* 3. 1328 Mbps */
		];

		samsung,dynamic_mipi_clk_timing_table = <
			/*<bitclk><>*/
			1362000000 /* clk id 0 default */
			1368000000 /* clk id 1 */
			1362000000 /* clk id 2 */
			1328000000 /* clk id 3 */
		>;

		samsung,dynamic_mipi_clk_sel_table = <
			/*<RAT><BAND><from><end><clk index>*/
			1	1	0	0	2
			1	2	0	0	1
			1	3	0	0	2
			1	4	0	0	1
			2	11	10562	10838	1
			2	12	9662	9938	1
			2	13	1162	1404	1
			2	13	1405	1513	3
			2	14	1537	1738	1
			2	15	4357	4381	3
			2	15	4382	4399	2
			2	15	4400	4458	1
			2	17	2237	2563	1
			2	18	2937	3088	1
			3	91	0	599	1
			3	92	600	1199	1
			3	93	1200	1709	1
			3	93	1710	1949	3
			3	94	1950	2399	1
			3	95	2400	2472	3
			3	95	2473	2509	2
			3	95	2510	2649	1
			3	97	2750	3449	1
			3	98	3450	3799	1
			3	102	5010	5179	1
			3	103	5180	5279	1
			3	104	5280	5379	1
			3	107	5730	5849	1
			3	108	5850	5999	3
			3	109	6000	6012	3
			3	109	6013	6049	2
			3	109	6050	6149	1
			3	110	6150	6449	1
			3	111	6450	6599	1
			3	115	8040	8689	1
			3	116	8690	8862	3
			3	116	8863	8899	2
			3	116	8900	9039	1
			3	118	9210	9659	1
			3	119	9660	9769	1
			3	120	9770	9869	1
			3	122	9920	10359	1
			3	124	36200	36349	1
			3	128	37750	37837	3
			3	128	37838	37949	2
			3	128	37950	38249	1
			3	129	38250	38427	3
			3	129	38428	38509	2
			3	129	38510	38649	1
			3	130	38650	39339	1
			3	130	39340	39649	3
			3	131	39650	40089	1
			3	131	40090	40477	3
			3	131	40478	40589	2
			3	131	40590	41589	1
			3	132	41590	41890	3
			3	132	41891	42040	2
			3	132	42041	43250	1
			3	132	43251	43589	3
			3	138	55240	55400	1
			3	138	55401	55742	3
			3	138	55743	55900	2
			3	138	55901	56739	1
			3	156	66436	67315	1
			3	156	67316	67335	3
			3	161	68586	68935	1
			4	51	0	0	1
			4	52	0	0	3
			4	53	0	0	1
			4	54	0	0	3
			4	55	0	0	2
			4	56	0	0	3
			5	61	0	0	3
			5	62	0	0	1
			5	71	0	0	3
			7	260	173800	175240	3
			7	260	175241	175980	2
			7	260	175981	178780	1
			7	263	185000	191980	1
			7	283	151600	160580	1
			7	326	123400	130380	1
		>;

		/* *************************************************************
		 * candela to index mappings
		 * **************************************************************
		 */
		samsung,candela_map_table_revA = < /* THIS TABLE USED FOR DIMMING */
		/* <idx> <from> <till> <gm2_wrdisbv> <cd> */
			0	0	0	5	2
			1	1	1	6	2
			2	2	2	7	3
			3	3	3	8	3
			4	4	4	12	4
			5	5	5	13	5
			6	6	6	14	5
			7	7	7	15	6
			8	8	8	16	7
			9	9	9	18	8
			10	10	10	20	9
			11	11	11	24	10
			12	12	12	25	10
			13	13	13	26	11
			14	14	14	28	12
			15	15	15	31	13
			16	16	16	33	14
			17	17	17	35	15
			18	18	18	37	16
			19	19	19	40	17
			20	20	20	42	18
			21	21	21	45	19
			22	22	22	47	21
			23	23	23	50	22
			24	24	24	52	23
			25	25	25	55	24
			26	26	26	57	25
			27	27	27	60	26
			28	28	28	63	27
			29	29	29	65	29
			30	30	30	68	30
			31	31	31	71	31
			32	32	32	74	32
			33	33	33	76	33
			34	34	34	79	35
			35	35	35	82	36
			36	36	36	85	37
			37	37	37	88	38
			38	38	38	91	40
			39	39	39	94	41
			40	40	40	97	42
			41	41	41	100	44
			42	42	42	103	45
			43	43	43	106	46
			44	44	44	109	48
			45	45	45	112	49
			46	46	46	115	50
			47	47	47	118	52
			48	48	48	121	53
			49	49	49	124	54
			50	50	50	127	56
			51	51	51	131	57
			52	52	52	134	59
			53	53	53	137	60
			54	54	54	140	62
			55	55	55	144	63
			56	56	56	147	64
			57	57	57	150	66
			58	58	58	153	67
			59	59	59	157	69
			60	60	60	160	70
			61	61	61	164	72
			62	62	62	167	73
			63	63	63	170	75
			64	64	64	174	76
			65	65	65	177	78
			66	66	66	181	79
			67	67	67	184	81
			68	68	68	188	82
			69	69	69	191	84
			70	70	70	195	85
			71	71	71	198	87
			72	72	72	202	89
			73	73	73	205	90
			74	74	74	209	92
			75	75	75	212	93
			76	76	76	216	95
			77	77	77	220	96
			78	78	78	223	98
			79	79	79	227	100
			80	80	80	231	101
			81	81	81	234	103
			82	82	82	238	105
			83	83	83	242	106
			84	84	84	245	108
			85	85	85	249	109
			86	86	86	253	111
			87	87	87	257	113
			88	88	88	260	114
			89	89	89	264	116
			90	90	90	268	118
			91	91	91	272	119
			92	92	92	276	121
			93	93	93	279	123
			94	94	94	283	124
			95	95	95	287	126
			96	96	96	291	128
			97	97	97	295	130
			98	98	98	299	131
			99	99	99	303	133
			100	100	100	306	135
			101	101	101	310	136
			102	102	102	314	138
			103	103	103	318	140
			104	104	104	322	142
			105	105	105	326	143
			106	106	106	330	145
			107	107	107	334	147
			108	108	108	338	149
			109	109	109	342	150
			110	110	110	346	152
			111	111	111	350	154
			112	112	112	354	156
			113	113	113	358	158
			114	114	114	362	159
			115	115	115	367	161
			116	116	116	371	163
			117	117	117	375	165
			118	118	118	379	167
			119	119	119	383	168
			120	120	120	387	170
			121	121	121	391	172
			122	122	122	395	174
			123	123	123	400	176
			124	124	124	404	177
			125	125	125	408	179
			126	126	126	412	181
			127	127	127	416	183
			128	128	128	421	185
			129	129	129	425	187
			130	130	130	429	189
			131	131	131	433	190
			132	132	132	438	192
			133	133	133	442	194
			134	134	134	446	196
			135	135	135	450	198
			136	136	136	455	200
			137	137	137	459	202
			138	138	138	463	204
			139	139	139	468	206
			140	140	140	472	207
			141	141	141	476	209
			142	142	142	481	211
			143	143	143	485	213
			144	144	144	489	215
			145	145	145	494	217
			146	146	146	498	219
			147	147	147	502	221
			148	148	148	507	223
			149	149	149	511	225
			150	150	150	516	227
			151	151	151	520	229
			152	152	152	525	231
			153	153	153	529	233
			154	154	154	533	235
			155	155	155	538	237
			156	156	156	542	239
			157	157	157	547	240
			158	158	158	551	242
			159	159	159	556	244
			160	160	160	560	246
			161	161	161	565	248
			162	162	162	569	250
			163	163	163	574	252
			164	164	164	579	254
			165	165	165	583	256
			166	166	166	588	258
			167	167	167	592	260
			168	168	168	597	262
			169	169	169	601	264
			170	170	170	606	266
			171	171	171	611	268
			172	172	172	615	271
			173	173	173	620	273
			174	174	174	624	275
			175	175	175	629	277
			176	176	176	634	279
			177	177	177	638	281
			178	178	178	643	283
			179	179	179	648	285
			180	180	180	652	287
			181	181	181	657	289
			182	182	182	662	291
			183	183	183	666	293
			184	184	184	671	295
			185	185	185	676	297
			186	186	186	680	299
			187	187	187	685	301
			188	188	188	690	303
			189	189	189	695	306
			190	190	190	699	308
			191	191	191	704	310
			192	192	192	709	312
			193	193	193	714	314
			194	194	194	718	316
			195	195	195	723	318
			196	196	196	728	320
			197	197	197	733	322
			198	198	198	738	324
			199	199	199	742	327
			200	200	200	747	329
			201	201	201	752	331
			202	202	202	757	333
			203	203	203	762	335
			204	204	204	767	337
			205	205	205	772	339
			206	206	206	776	341
			207	207	207	781	344
			208	208	208	786	346
			209	209	209	791	348
			210	210	210	796	350
			211	211	211	801	352
			212	212	212	806	354
			213	213	213	811	357
			214	214	214	816	359
			215	215	215	820	361
			216	216	216	825	363
			217	217	217	830	365
			218	218	218	835	367
			219	219	219	840	370
			220	220	220	845	372
			221	221	221	850	374
			222	222	222	855	376
			223	223	223	860	378
			224	224	224	865	381
			225	225	225	870	383
			226	226	226	875	385
			227	227	227	880	387
			228	228	228	885	389
			229	229	229	890	392
			230	230	230	895	394
			231	231	231	900	396
			232	232	232	905	398
			233	233	233	910	400
			234	234	234	915	403
			235	235	235	920	405
			236	236	236	926	407
			237	237	237	931	409
			238	238	238	936	412
			239	239	239	941	414
			240	240	240	946	416
			241	241	241	951	418
			242	242	242	956	421
			243	243	243	961	423
			244	244	244	966	425
			245	245	245	971	427
			246	246	246	977	430
			247	247	247	982	432
			248	248	248	987	434
			249	249	249	992	436
			250	250	250	997	439
			251	251	251	1002	441
			252	252	252	1007	443
			253	253	253	1013	445
			254	254	254	1018	448
			255	255	255	1023	450
		>;

		samsung,hbm_candela_map_table_revA = <
		/* <idx> <from> <till> <gm2_wrdisbv> <cd> <auto> */
			0	256	256	5	451	0
			1	257	257	8	452	0
			2	258	258	15	454	0
			3	259	259	22	455	0
			4	260	260	29	457	0
			5	261	261	36	459	0
			6	262	262	44	461	0
			7	263	263	51	462	0
			8	264	264	58	464	0
			9	265	265	65	466	0
			10	266	266	72	468	0
			11	267	267	79	469	0
			12	268	268	86	471	0
			13	269	269	93	473	0
			14	270	270	100	474	0
			15	271	271	107	476	0
			16	272	272	115	478	0
			17	273	273	122	480	0
			18	274	274	129	482	0
			19	275	275	136	483	0
			20	276	276	143	485	0
			21	277	277	150	487	0
			22	278	278	157	488	0
			23	279	279	164	490	0
			24	280	280	171	492	0
			25	281	281	178	493	0
			26	282	282	185	495	0
			27	283	283	193	497	0
			28	284	284	200	499	0
			29	285	285	207	501	0
			30	286	286	214	502	0
			31	287	287	221	504	0
			32	288	288	228	506	0
			33	289	289	235	507	0
			34	290	290	242	509	0
			35	291	291	249	511	0
			36	292	292	256	513	0
			37	293	293	264	515	0
			38	294	294	271	516	0
			39	295	295	278	518	0
			40	296	296	285	520	0
			41	297	297	292	521	0
			42	298	298	299	523	0
			43	299	299	306	525	0
			44	300	300	313	526	0
			45	301	301	320	528	0
			46	302	302	327	530	0
			47	303	303	335	532	0
			48	304	304	342	534	0
			49	305	305	349	535	0
			50	306	306	356	537	0
			51	307	307	363	539	0
			52	308	308	370	540	0
			53	309	309	377	542	0
			54	310	310	384	544	0
			55	311	311	391	546	0
			56	312	312	398	547	0
			57	313	313	406	549	0
			58	314	314	413	551	0
			59	315	315	420	553	0
			60	316	316	427	554	0
			61	317	317	434	556	0
			62	318	318	441	558	0
			63	319	319	448	559	0
			64	320	320	455	561	0
			65	321	321	462	563	0
			66	322	322	469	565	0
			67	323	323	476	566	0
			68	324	324	484	568	0
			69	325	325	491	570	0
			70	326	326	498	572	0
			71	327	327	505	573	0
			72	328	328	512	575	0
			73	329	329	519	577	0
			74	330	330	526	579	0
			75	331	331	533	580	0
			76	332	332	540	582	0
			77	333	333	547	584	0
			78	334	334	555	586	0
			79	335	335	562	587	0
			80	336	336	569	589	0
			81	337	337	576	591	0
			82	338	338	583	592	0
			83	339	339	590	594	0
			84	340	340	597	596	0
			85	341	341	604	598	0
			86	342	342	611	599	0
			87	343	343	618	601	0
			88	344	344	626	603	0
			89	345	345	633	605	0
			90	346	346	640	606	0
			91	347	347	647	608	0
			92	348	348	654	610	0
			93	349	349	661	612	0
			94	350	350	668	613	0
			95	351	351	675	615	0
			96	352	352	682	617	0
			97	353	353	689	618	0
			98	354	354	696	620	0
			99	355	355	704	622	0
			100	356	356	711	624	0
			101	357	357	718	625	0
			102	358	358	725	627	0
			103	359	359	732	629	0
			104	360	360	739	631	0
			105	361	361	746	632	0
			106	362	362	753	634	0
			107	363	363	760	636	0
			108	364	364	767	637	0
			109	365	365	775	639	0
			110	366	366	782	641	0
			111	367	367	789	643	0
			112	368	368	796	645	0
			113	369	369	803	646	0
			114	370	370	810	648	0
			115	371	371	817	650	0
			116	372	372	824	651	0
			117	373	373	831	653	0
			118	374	374	838	655	0
			119	375	375	846	657	0
			120	376	376	853	658	0
			121	377	377	860	660	0
			122	378	378	867	662	0
			123	379	379	874	664	0
			124	380	380	881	665	0
			125	381	381	888	667	0
			126	382	382	895	669	0
			127	383	383	902	670	0
			128	384	384	909	672	0
			129	385	385	917	674	0
			130	386	386	924	676	0
			131	387	387	931	678	0
			132	388	388	938	679	0
			133	389	389	945	681	0
			134	390	390	952	683	0
			135	391	391	959	684	0
			136	392	392	966	686	0
			137	393	393	973	688	0
			138	394	394	980	689	0
			139	395	395	987	691	0
			140	396	396	995	693	0
			141	397	397	1002	695	0
			142	398	398	1009	697	0
			143	399	399	1016	698	0
			144	400	400	1023	700	0
		>;

		samsung,aod_candela_map_table_revA = <
		/*   <idx>   <from>  <till>  <gm2_wrdisbv> <cd> */
			0	0	11	0	2
			1	12	29	0	10
			2	30	52	0	30 
			3	53	255	0	60
		>;

		samsung,gamma_mode2_normal_tx_cmds_revA=[
			29 00 00 00 00 00 02 53 20				/* WRCTRLD  0x20=normal, 0x28=smooth transition */
			29 00 00 00 00 00 04 B5 19 CD 16		/* 1. ELVSS control: TSET=0x19 for 25 degree */
			29 00 00 00 00 00 03 51 03 FF			/* WRDISBV 450 nit */
			29 00 00 00 00 00 03 B0 BF 93
			29 00 00 00 00 00 06 93 27 E1 55 CD 00	/* IRC Mode Setting */
			29 01 00 00 00 00 02 F7 0F				/* Update key */
		];

		samsung,gamma_mode2_hbm_tx_cmds_revA=[
			29 00 00 00 00 00 02 53 E0				/* HBM: 0xE0=normal , 0x28=smooth transition */
			29 00 00 00 00 00 04 B5 FF CD FF				/* 1. ELVSS control: TSET=0x19 for 25 degree */
			29 00 00 00 00 00 03 51 03 FF			/* WRDISBV 450 nit */
			29 00 00 00 00 00 03 B0 BF 93
			29 00 00 00 00 00 06 93 27 E1 55 CD 00	/* IRC Mode Setting */
			29 01 00 00 00 00 02 F7 0F				/* Update key */
		];

		/* *************************************************************
		 *  VRR
		 * **************************************************************
		 */
		/* gamma compensation for 48/96hz mode */
		samsung,vrr_gm2_gamma_comp_tx_cmds_revA = [
			29 00 00 00 00 00 03 B0 6F C8
			29 00 00 00 00 00 70 C8		/* 2. C8h 0x6F ~ 0xDD, 37 * 3 = 111 bytes */
					00 00 00 00 00 00 00 00 00 00
					00 00 00 00 00 00 00 00 00 00
					00 00 00 00 00 00 00 00 00 00
					00 00 00 00 00 00 00 00 00 00
					00 00 00 00 00 00 00 00 00 00
					00 00 00 00 00 00 00 00 00 00
					00 00 00 00 00 00 00 00 00 00
					00 00 00 00 00 00 00 00 00 00
					00 00 00 00 00 00 00 00 00 00
					00 00 00 00 00 00 00 00 00 00
					00 00 00 00 00 00 00 00 00 00
					00

			29 00 00 00 00 00 03 B0 13 C7
			29 00 00 00 00 00 95 C7		/* 5. C7h 0x13 ~ 0xA6, 37 * 4 = 148 bytes */
					00 00 00 00 00 00 00 00 00 00
					00 00 00 00 00 00 00 00 00 00
					00 00 00 00 00 00 00 00 00 00
					00 00 00 00 00 00 00 00 00 00
					00 00 00 00 00 00 00 00 00 00
					00 00 00 00 00 00 00 00 00 00
					00 00 00 00 00 00 00 00 00 00
					00 00 00 00 00 00 00 00 00 00
					00 00 00 00 00 00 00 00 00 00
					00 00 00 00 00 00 00 00 00 00
					00 00 00 00 00 00 00 00 00 00
					00 00 00 00 00 00 00 00 00 00
					00 00 00 00 00 00 00 00 00 00
					00 00 00 00 00 00 00 00 00 00
					00 00 00 00 00 00 00 00
		];

		samsung,vrr_tx_cmds_revA = [
			29 01 00 00 00 00 01 00		/* 0. NULL packet to send vrr cmds at once, to prevent flicker during HS/NS transition */

			29 00 00 00 00 00 03 F0 5A 5A	/* TEST KEY Enable */
			29 00 00 00 00 00 18 BD
						01 00 00 80 00 12 60 00 01 70 00 00 00 0B 00 00
						00 00 00 00 02 00 44
						/*  LFD Setting
						 * HS: 01 00 00 80 00 12 60 00 01 70 00 00 00 0B 00 00 00 00 00 00 02 00 44
						 * NS: 01 00 00 80 00 00 60 00 01 70 00 00 00 01 00 00 00 00 00 00 02 00 F0
						 */
			29 00 00 00 00 00 05 F2 41 14 BA 40		/* VRRHz_HS */
			29 00 00 00 00 00 03 60 08 01			/* VRRHz_HS */
			29 00 00 00 00 00 03 B0 05 F2			/* VRR_CMDOFFSET_VFP_05 */
			29 00 00 00 00 00 03 F2 00 00
			29 00 00 00 00 00 03 B0 0C F2			/* VRR_CMDOFFSET_VFP_0C */
			29 00 00 00 00 00 03 F2 00 00
			29 00 00 00 00 00 03 B0 43 B1			/* VRR_CMDOFFSET_AOR */
			29 00 00 00 00 00 19 B1					/* VRR_CMDID_AOR */
					07 00 07 00 07 00 07 00
					07 00 07 00 07 00 07 00
					07 00 07 00 06 DC 01 20
			29 00 00 00 00 00 03 B0 2F F4
			29 00 00 00 00 00 08 F4 00 00 00 00 00 00 00 /* VBIAS Setting */
			29 00 00 00 00 00 03 B0 47 F4
			29 00 00 00 00 00 08 F4 00 00 00 00 00 00 00 /* VAINT Setting */
			29 00 00 00 00 00 02 B9 01	/* TE modulation
							 * 00: default,
							 * 11: 60HS
							 * TE operates at every 2 frame
							 * TE_SEL & TE_FRAME_SEL = 1
							 */
			29 00 00 00 00 00 02 F7 0F		/* 12. LTPS update */
			29 01 00 00 00 00 03 F0 A5 A5	/* TEST KEY Disable */
		];

		samsung,vrr_tx_cmds_revD = [
			29 01 00 00 00 00 01 00		/* 0. NULL packet to send vrr cmds at once, to prevent flicker during HS/NS transition */

			29 00 00 00 00 00 03 F0 5A 5A	/* TEST KEY Enable */
			29 00 00 00 00 00 18 BD
						01 00 00 80 00 12 60 00 01 70 00 00 00 0B 00 00
						00 00 00 00 02 00 44
						/*  LFD Setting
						 * HS: 01 00 00 80 00 12 60 00 01 70 00 00 00 0B 00 00 00 00 00 00 02 00 44
						 * NS: 01 00 00 80 00 00 60 00 01 70 00 00 00 01 00 00 00 00 00 00 02 00 F0
						 */
			29 00 00 00 00 00 05 F2 41 14 BA 40		/* VRRHz_HS */
			29 00 00 00 00 00 03 60 08 01			/* VRRHz_HS */
			29 00 00 00 00 00 03 B0 05 F2			/* VRR_CMDOFFSET_VFP_05 */
			29 00 00 00 00 00 03 F2 00 00
			29 00 00 00 00 00 03 B0 0C F2			/* VRR_CMDOFFSET_VFP_0C */
			29 00 00 00 00 00 03 F2 00 00
			29 00 00 00 00 00 03 B0 43 B1			/* VRR_CMDOFFSET_AOR */
			29 00 00 00 00 00 19 B1					/* VRR_CMDID_AOR */
					07 00 07 00 07 00 07 00
					07 00 07 00 07 00 07 00
					07 00 07 00 06 DC 01 20
			29 00 00 00 00 00 03 B0 2F F4
			29 00 00 00 00 00 08 F4 00 00 00 00 00 00 00 /* VBIAS Setting */
			29 00 00 00 00 00 03 B0 47 F4
			29 00 00 00 00 00 09 F4 00 00 00 00 00 00 00 00 /* VAINT Setting */
			29 00 00 00 00 00 02 B9 01	/* TE modulation
							 * 01: default,
							 * 11: 60HS
							 * TE operates at every 2 frame
							 * TE_SEL & TE_FRAME_SEL = 1
							 */
			29 00 00 00 00 00 02 F7 0F		/* 12. LTPS update */
			29 01 00 00 00 00 03 F0 A5 A5	/* TEST KEY Disable */
		];

		samsung,rsc_4_frame_idle;

		samsung,support_vrr_based_bl; /* VRR Variable Refresh Rate */
		samsung,support_lfd; /* Low Frequency Driving mode for HOP display */
		/* Use HW TE modulation using B9h TECTRL.
		 * If choose SW TE modulation, DDI generates TE at 120Hz even 60HS mode.
		 * In result, RSC of MDP should wake-up in every 120Hz TE, so it consumes more power source.
		 * To reduce power consumption, enable HW TE modulation, and disable SW TE modulation.
		 */
		/* samsung,support_te_mod; */ /* VRR: TE modulation for TOP display */
		/* *************************************************************
		 *   ALPM
		 * *************************************************************
		 */
		samsung,self_grid_on_revA = [
			29 00 00 00 00 00 03 F0 5A 5A	/* TEST KEY Enable */
  			29 00 00 00 00 00 0E 7C 00 01 00 1F 00 00 00 00 08 9F 06 E7 1E
			29 01 00 00 00 00 03 F0 A5 A5	/* TEST KEY Disable */
		];

		samsung,self_grid_off_revA = [
			29 00 00 00 22 00 03 F0 5A 5A	/* TEST KEY Enable - delay 34ms after dipslay_on */
			29 00 00 00 00 00 03 7C 00 00
			29 01 00 00 00 00 03 F0 A5 A5	/* TEST KEY Disable */
		];

		samsung,lpm_on_tx_cmds_revA = [
			29 00 00 00 00 00 03 F0 5A 5A	/* TEST KEY Enable */
			29 00 00 00 00 00 0A BB 15 0C 01 20	06 DA 00 90 00 /* HLPM control */
			29 00 00 00 00 00 18 BD
				01 00 00 80 00 08 40 00 01 70 00 1D 00 0B 00 00
				00 00 00 00 02 00 14
			29 00 00 00 00 00 03 B0 66 F4
			29 00 00 00 00 00 02 F4 04 		/* 00 : AVS OFF, 04 : AVS ON */
			29 00 00 00 00 00 02 53 22		/* 22 : HLPM 60/30/10nit On, 23 2nit On */
			29 00 00 00 00 00 03 B0 0B F4
			29 00 00 00 00 00 02 F4 AA 		/* AVC2 OFF */
			29 00 00 00 00 00 03 B0 12 F2
			29 00 00 00 00 00 03 F2 08 10
			29 00 00 00 00 00 02 B9 01		/* HW TE modulation disable */
			29 00 00 00 00 00 02 F7 0F		/* Gamma, LTPS(AID) update */
			29 01 00 00 00 00 03 F0 A5 A5	/* TEST KEY Disable */
		];
		samsung,lpm_off_tx_cmds_revA = [
			29 00 00 00 00 00 03 F0 5A 5A	/* TEST KEY Enable */
			29 00 00 00 00 00 03 B0 0B F4
			29 00 00 00 00 00 02 F4 EA
			29 00 00 00 00 00 02 BB 01
			29 00 00 00 00 00 02 53 28		/* WRCTRLD: Dimming speed: 0x20=normal transition, 0x28=smooth transition */
			39 00 00 00 00 00 03 B0 53 B5	/* EL ON1 No toggle */
			39 01 00 00 0A 00 02 B5 00
			29 00 00 00 00 00 02 F7 0F		/* Gamma, LTPS(AID) update */
			29 01 00 00 00 00 03 F0 A5 A5	/* TEST KEY Disable */
		];
		/* ALPM/HLPM 2nit or 60nit On Commands */
		samsung,lpm_2nit_tx_cmds_revA = [29 00 00 00 00 00 02 53 23];	/* HLPM on*/
		samsung,lpm_10nit_tx_cmds_revA = [29 00 00 00 00 00 02 53 22];	/* ALPM on*/
		samsung,lpm_30nit_tx_cmds_revA = [29 00 00 00 00 00 02 53 22];	/* ALPM on*/
		samsung,lpm_60nit_tx_cmds_revA = [29 00 00 00 00 00 02 53 22];	/* ALPM on*/

		samsung,lpm_ctrl_hlpm_2nit_tx_cmds_revA		= [29 00 00 00 00 00 0A BB 15 0C 06 DA 06 DA 00 90 00];
		samsung,lpm_ctrl_hlpm_10nit_tx_cmds_revA	= [29 00 00 00 00 00 0A BB 15 0C 06 10 06 DA 00 90 00];
		samsung,lpm_ctrl_hlpm_30nit_tx_cmds_revA	= [29 00 00 00 00 00 0A BB 15 0C 04 20 06 DA 00 90 00];
		samsung,lpm_ctrl_hlpm_60nit_tx_cmds_revA	= [29 00 00 00 00 00 0A BB 15 0C 01 20 06 DA 00 90 00];

		/* HLPM / ALPM brightness Commands: default alpm 2nit */
		samsung,lpm_brightnes_tx_cmds_revA		= [
			29 00 00 00 00 00 03 F0 5A 5A	/* TEST KEY Enable */
			29 00 00 00 00 00 0A BB 15 0C 01 20	06 DA 00 90 55 /* HLPM control */
			29 00 00 00 00 00 18 BD 
				01 00 00 80 00 08 40 00 01 70 00 00 00 0B 00 00
				00 00 00 00 02 00 14
			29 00 00 00 00 00 02 53 00
			29 00 00 00 00 00 02 F7 0F		/* Gamma, LTPS(AID) update */
			29 01 00 00 00 00 03 F0 A5 A5	/* TEST KEY Disable */
		];
		samsung,alpm_rx_cmds_revA= [06 01 00 00 00 00 01 BB 01 08];

		/* *************************************************************
		 * VINT
		 * *************************************************************
		 */
		 samsung,vint_tx_cmds_revA = [
			29 00 00 00 00 00 03 F0 5A 5A	/* TEST KEY Enable */
			29 00 00 00 00 00 03 B0 00 F4
			29 00 00 00 00 00 02 F4 10
			29 00 00 00 00 00 02 F7 0F
			29 01 00 00 00 00 03 F0 A5 A5	/* TEST KEY Disable */
		];

		 samsung,vint_tx_cmds_revC = [
			29 00 00 00 00 00 03 F0 5A 5A	/* TEST KEY Enable */
			29 00 00 00 00 00 03 B0 1C F4
			29 00 00 00 00 00 02 F4 10
			29 00 00 00 00 00 02 F7 0F
			29 01 00 00 00 00 03 F0 A5 A5	/* TEST KEY Disable */
		];

		/* *************************************************************
		 * flash to get vbias data for HOP display (gamma mode2)
		 * VBIAS: 14(cmd) x 3(temperature) x 2(HS/NS) = 84 bytes: F0000 ~ F0053
		 * checksum: 2 bytes: F0054 ~ F0055
		 * Flash write pass: 1 byte: F0056
		 * VBIAS HS/NS mode: 2 bytes: F0057 ~ F0058
		 *
		 * *************************************************************
		 */
		samsung,flash_vbias_start_addr = <0xF0000>;

		samsung,flash_vbias_tot_len = <89>;
		samsung,flash_vbias_one_mode_len = <22>;

		samsung,flash_vbias_ns_temp_warm_offset = <0x00>;
		samsung,flash_vbias_ns_temp_cool_offset = <0x0E>;
		samsung,flash_vbias_ns_temp_cold_offset = <0x1C>;
		samsung,flash_vbias_hs_temp_warm_offset = <0x2A>;
		samsung,flash_vbias_hs_temp_cool_offset = <0x38>;
		samsung,flash_vbias_hs_temp_cold_offset = <0x46>;

		samsung,flash_vbias_checksum_offset = <0x56>;

		samsung,flash_vbias_mtp_one_mode_len = <32>;
		samsung,vbias_mtp_rx_cmds_revA  = [06 01 00 00 00 00 01 F4 20 2F]; /* NS & T > 0 : F4h 48nd ~ 54th, and 72nd ~ 79th : offset 0x2F, size = 32 = 0x16 */

		/* *************************************************************
		 * Adjust te to avoid tearing
		 * *************************************************************
		 */		
		samsung,adjust_te_cmds_revA = [
			29 00 00 00 00 00 03 F0 5A 5A	/* TEST KEY Enable */
			29 00 00 00 00 00 06 B9 01 06 D6 06 FB
			29 01 00 00 00 00 03 F0 A5 A5	/* TEST KEY Disable */
		];

		/* *************************************************************
		 * flash
		 * *************************************************************
		 */

		samsung,flash_gamma_pre_tx_cmds1_revA = [
			/* pre-condition for reading flash gamma data */
			39 01 00 00 00 00 03 F0 5A 5A
			39 01 00 00 00 00 03 F1 F1 A2
			39 01 00 00 00 00 02 C0 02
			39 01 00 00 01 00 04 71 03 00 00 					/* SPSRAM Access Enable & wait 1ms */
			39 01 00 00 00 00 0A C1 00 00 06 00 00 00 00 00 00 	/* Write enable */
			39 01 00 00 01 00 02 C0 03 							/* Flash excute & wait 1ms */
			29 00 00 00 00 00 0A C1 00 00 01 00 02 00 80 00 00	/* Flash Control */
			39 01 00 00 0A 00 02 C0 03							/* Flash excute & wait 10ms */
		];

		samsung,flash_gamma_post_tx_cmds_revA = [
		/* post-condition for reading flash gamma data */
			39 01 00 00 00 00 02 C0 00
			39 01 00 00 00 00 03 F0 A5 A5
			39 01 00 00 00 00 03 F1 A5 A5
		];

		samsung,flash_gamma_tx_cmds_revA = [
		/* reading flash gamma data */
			39 01 00 00 00 00 0A C1 00 00 6B 00 00 00 C0 00 01	 /* ADDR & Size setting */
			39 01 00 00 00 00 02 C0 03
		];

		/* 0x0E 1byte read */
		samsung,flash_gamma_rx_cmds_revA	= [06 01 00 00 00 00 01 6E 01 00];	/* read FB 13th, len=1, offset=12 */
		samsung,br_tables {
			vrr60@0 {
				samsung,flash_gamma_data_read_addr = <4 5 6>;
			};
		};

		/*
		* ************************************************************************************************************************
		*  DMS (Dynamic Mode Switch)
		* ************************************************************************************************************************
		*/

		qcom,mdss-dsi-display-timings {
			qxga120hs {
				qcom,display-topology = <2 2 1>;
				qcom,default-topology-index = <0>;

				qcom,mdss-dsi-panel-width = <2208>;
				qcom,mdss-dsi-panel-height = <1768>;

				qcom,mdss-dsi-h-pulse-width = <56>;
				qcom,mdss-dsi-h-back-porch = <60>;
				qcom,mdss-dsi-h-front-porch = <60>;
				qcom,mdss-dsi-h-sync-skew = <0>;

				qcom,mdss-dsi-v-pulse-width = <56>;
				qcom,mdss-dsi-v-back-porch = <60>;
				qcom,mdss-dsi-v-front-porch = <52>;

				qcom,mdss-mdp-transfer-time-us = <7533>;

				samsung,mdss-dsi-sot-hs-mode;
				qcom,mdss-dsi-panel-framerate = <120>;

				qcom,mdss-dsi-panel-clockrate = <1362000000>; /* 1362Mhz*/

				qcom,mdss-dsi-panel-phy-timings = [00 2C 0C 0C 29 26 0C 0C 08 03 04 00 24 1B];	/* SM8250 : dsi_phy_v4_0 */

				qcom,mdss-dsi-t-clk-pre = <0x24>;
				qcom,mdss-dsi-t-clk-post = <0x1B>;

				qcom,mdss-dsi-timing-switch-command = [ 
					29 00 00 00 00 00 03 F0 5A 5A		/* TEST KEY2 Enable */
					29 00 00 00 00 00 05 F2 41 14 BA 40		/* HS */
					29 00 00 00 00 00 03 60 08 00			/* 120Hz_HS */
					29 00 00 00 00 00 03 B0 05 F2
					29 00 00 00 00 00 03 F2 00 08			/* VFP_return */
					29 00 00 00 00 00 03 B0 0C F2
					29 00 00 00 00 00 03 F2 00 08			/* VFP_return */
					29 00 00 00 00 00 03 B0 43 B1
					29 00 00 00 00 00 19 B1					/* Common_AOR */
							07 00 07 00 07 00 07 00
							07 00 07 00 07 00 07 00
							07 00 07 00 06 DC 01 20
					29 00 00 00 00 00 02 F7 0F
					29 01 00 00 00 00 03 F0 A5 A5		/* TEST KEY2 Disable */
				]; 

				qcom,mdss-dsi-on-command = [
					29 00 00 00 00 00 03 F0 5A 5A	/* TEST KEY2 Enable */

					/* **** INTERFACE SETTING **** */

					07 00 00 00 00 00 01 01			/* DSC enable :  Compression Mode*/

					/* W/A: transmit dummy 2C command before sleep out. (requested by dlab)
					 * In display off -> AOD on sequence, self display features allows
					 * 4C cmd transmission without 2C cmd, and it causes sand strom image due to HAC DDI HW chip...
					 * To prevent the issue, transmit dummy 2C command before sleep out command.
					 */
					29 00 00 00 00 00 04 2C 00 00 00

					/* **** SLEEP OUT **** */
					05 01 00 00 78 00 01 11		/* Sleep out, wait 120ms */

					/* **** SIGNAL DC VALUE SETTING **** */
					29 00 00 00 00 00 03 B0 0A CB	/* Signal DC Value */
					29 00 00 00 00 00 02 CB 0F
					29 01 00 00 00 00 02 F7 0F

					/* **** COMMON SETTING **** */

					29 00 00 00 00 00 02 35 00		/* TE Vsync On */

					29 00 00 00 00 00 03 ED 04 40	/* ERR_FG Setting */

					29 00 00 00 00 00 02 9B 00		/* enable UDC */

					29 00 00 00 00 00 0D B9 01 06 E5 06 FB 00 00 00 00 11 01 03		/* TSP SYNC Enable */

					29 00 00 00 00 00 18 BD											/*  LFD Setting */
						01 00 00 80 00 01 40 00 01 70 00 00 00 0B 00 00
						00 00 00 00 02 00 14

					/* **** Freq. Mode Change Setting **** */
					29 00 00 00 00 00 05 F2 41 14 BA 40		/* 120Hz_HS */
					29 00 00 00 00 00 03 60 08 00			/* 120Hz_HS */

					/* **** VFP & AOR setting **** */
					29 00 00 00 00 00 03 B0 05 F2
					29 00 00 00 00 00 03 F2 00 08			/* VFP_return */
					29 00 00 00 00 00 03 B0 0C F2
					29 00 00 00 00 00 03 F2 00 08			/* VFP_return */
					29 00 00 00 00 00 03 B0 43 B1
					29 00 00 00 00 00 19 B1					/* Common_AOR */
							07 00 07 00 07 00 07 00
							07 00 07 00 07 00 07 00
							07 00 07 00 06 DC 01 20
					29 00 00 00 00 00 02 F7 0F				/* Update key */

					/* **** Smooth Dimming Setting **** */
					29 00 00 00 00 00 03 B0 0B B1
					29 00 00 00 00 00 02 B1 08
					29 00 00 00 00 00 02 F7 0F				/* Update key */

					/* **** DIA Setting **** */
					29 00 00 00 00 00 03 B0 9D 64
					29 00 00 00 00 00 02 64 09

					/* **** BRIGHTNESS SETTING **** */

					29 00 00 00 00 00 03 FC 5A 5A
					29 00 00 00 00 00 02 53 20				/* WRCTRLD */
					29 00 00 00 00 00 03 51 03 FF			/* WRDISBV 450 nit */
					29 00 00 00 00 00 02 F7 0F				/* Update key */
					29 00 00 00 00 00 03 FC A5 A5

					29 01 00 00 00 00 03 F0 A5 A5	/* TEST KEY2 Disable */
				];

				qcom,mdss-dsi-off-command = [
					29 01 00 00 00 00 03 9F A5 A5		/* TEST KEY1 Enable */
					29 00 00 00 00 00 03 F0 5A 5A	/* TEST KEY2 Enable */

					29 00 00 00 00 00 03 B0 39 F4		/* Vaint SET(-4.2V) */
					29 00 00 00 00 00 08 F4 80 80 80 80 80 80 80 /* 0x80 :   -4.2V */
					29 00 00 00 00 00 03 B0 47 F4
					29 00 00 00 00 00 08 F4 80 80 80 80 80 80 80 /* 0x80 :   -4.2V */

					05 00 00 00 00 00 01 28				/* Display off */

					05 01 00 00 0A 00 01 10				/* wait 10ms(0x0A) */

					29 00 00 00 00 00 03 B0 0A CB	/* Signal DC Value Setting */
					29 00 00 00 00 00 02 CB 4F
					29 00 00 00 00 00 02 F7 0F

					29 00 00 00 00 00 03 B0 04 F2	/* Oscillator off  & wait 120ms */
					29 00 00 00 00 00 02 F2 02
					29 00 00 00 00 00 02 F7 0F

					29 00 00 00 00 00 03 B0 07 EF	/* power off & change GPO */
					29 00 00 00 00 00 02 EF 55
					29 00 00 00 00 00 02 F7 0F

					29 01 00 00 78 00 03 F0 A5 A5	/* TEST KEY2 Enable */
					29 01 00 00 00 00 03 9F 5A 5A		/* TEST KEY1 disable */
				];

				qcom,mdss-dsi-on-command-state = "dsi_lp_mode"; /* TBD */
				qcom,mdss-dsi-off-command-state = "dsi_hs_mode";

				qcom,partial-update-enabled = "single_roi";
				qcom,panel-roi-alignment=<1104 34 1104 34 1104 34>;
				qcom,compression-mode = "dsc";
				qcom,lm-split = <1104 1104>;
				qcom,mdss-dsc-encoders = <2>;
				qcom,mdss-dsc-slice-height = <34>;
				qcom,mdss-dsc-slice-width = <1104>;
				qcom,mdss-dsc-slice-per-pkt = <1>;
				qcom,mdss-dsc-bit-per-component = <8>;
				qcom,mdss-dsc-bit-per-pixel = <8>;
				qcom,mdss-dsc-block-prediction-enable;
			};
			qxga96hs {
				qcom,display-topology = <2 2 1>;
				qcom,default-topology-index = <0>;

				qcom,mdss-dsi-panel-width = <2208>;
				qcom,mdss-dsi-panel-height = <1768>;

				qcom,mdss-dsi-h-pulse-width = <56>;
				qcom,mdss-dsi-h-back-porch = <60>;
				qcom,mdss-dsi-h-front-porch = <60>;
				qcom,mdss-dsi-h-sync-skew = <0>;

				qcom,mdss-dsi-v-pulse-width = <56>;
				qcom,mdss-dsi-v-back-porch = <60>;
				qcom,mdss-dsi-v-front-porch = <56>;

				qcom,mdss-mdp-transfer-time-us = <7533>;

				samsung,mdss-dsi-sot-hs-mode;
				qcom,mdss-dsi-panel-framerate = <96>;

				qcom,mdss-dsi-panel-clockrate = <1362000000>; /* 1362Mhz*/

				qcom,mdss-dsi-panel-phy-timings = [00 2C 0C 0C 29 26 0C 0C 08 03 04 00 24 1B];	/* SM8250 : dsi_phy_v4_0 */

				qcom,mdss-dsi-t-clk-pre = <0x24>;
				qcom,mdss-dsi-t-clk-post = <0x1B>;

				qcom,mdss-dsi-timing-switch-command = [ 
					29 00 00 00 00 00 03 F0 5A 5A		/* TEST KEY2 Enable */
					29 00 00 00 00 00 05 F2 41 14 BA 40		/* HS */
					29 00 00 00 00 00 03 60 08 00			/* 120Hz_HS */
					29 00 00 00 00 00 03 B0 05 F2
					29 00 00 00 00 00 03 F2 01 CC			/* 96Hz_VFP */
					29 00 00 00 00 00 03 B0 43 B1
					29 00 00 00 00 00 03 B1					/* 96Hz_AOR */
							08 C4 08 C4 08 C4 08 C4
							08 C4 08 C4 08 C4 08 C4
							08 C4 08 C4 08 97 01 69
					29 00 00 00 00 00 02 F7 0F
					29 01 00 00 00 00 03 F0 A5 A5		/* TEST KEY2 Disable */
				]; 

				qcom,mdss-dsi-on-command = [
					29 00 00 00 00 00 03 F0 5A 5A	/* TEST KEY2 Enable */

					/* **** INTERFACE SETTING **** */

					07 00 00 00 00 00 01 01			/* DSC enable :  Compression Mode*/

					/* W/A: transmit dummy 2C command before sleep out. (requested by dlab)
					 * In display off -> AOD on sequence, self display features allows
					 * 4C cmd transmission without 2C cmd, and it causes sand strom image due to HAC DDI HW chip...
					 * To prevent the issue, transmit dummy 2C command before sleep out command.
					 */
					29 00 00 00 00 00 04 2C 00 00 00

					/* **** SLEEP OUT **** */
					05 01 00 00 78 00 01 11		/* Sleep out, wait 120ms */

					/* **** SIGNAL DC VALUE SETTING **** */
					29 00 00 00 00 00 03 B0 0A CB	/* Signal DC Value Setting & wait 120ms */
					29 00 00 00 00 00 02 CB 0F
					29 01 00 00 00 00 02 F7 0F

					/* **** COMMON SETTING **** */

					29 00 00 00 00 00 02 35 00		/* TE Vsync On */

					29 00 00 00 00 00 03 ED 04 40	/* ERR_FG Setting */

					29 00 00 00 00 00 02 9B 00		/* enable UDC */

					29 00 00 00 00 00 0D B9 01 06 E5 06 FB 00 00 00 00 11 01 03		/* TSP SYNC Enable */

					29 00 00 00 00 00 18 BD											/*  LFD Setting */
						01 00 00 80 00 01 40 00 01 70 00 00 00 0B 00 00
						00 00 00 00 02 00 14

					/* **** Freq. Mode Change Setting **** */
					29 00 00 00 00 00 05 F2 41 14 BA 40		/* 120Hz_HS */
					29 00 00 00 00 00 03 60 08 00			/* 120Hz_HS */

					/* **** VFP & AOR setting **** */
					29 00 00 00 00 00 03 B0 05 F2
					29 00 00 00 00 00 03 F2 01 CC			/* 96Hz_VFP */
					29 00 00 00 00 00 03 B0 43 B1
					29 00 00 00 00 00 19 B1					/* 96Hz_AOR */
							08 C4 08 C4 08 C4 08 C4
							08 C4 08 C4 08 C4 08 C4
							08 C4 08 C4 08 97 01 69					
					29 00 00 00 00 00 02 F7 0F				/* Update key */

					/* **** Smooth Dimming Setting **** */
					29 00 00 00 00 00 03 B0 0B B1
					29 00 00 00 00 00 02 B1 08
					29 00 00 00 00 00 02 F7 0F				/* Update key */

					/* **** DIA Setting **** */
					29 00 00 00 00 00 03 B0 9D 64
					29 00 00 00 00 00 02 64 09

					/* **** BRIGHTNESS SETTING **** */

					29 00 00 00 00 00 03 FC 5A 5A
					29 00 00 00 00 00 02 53 20				/* WRCTRLD */
					29 00 00 00 00 00 03 51 03 FF			/* WRDISBV 450 nit */
					29 00 00 00 00 00 02 F7 0F				/* Update key */
					29 00 00 00 00 00 03 FC A5 A5

					29 01 00 00 00 00 03 F0 A5 A5	/* TEST KEY2 Disable */
				];

				qcom,mdss-dsi-off-command = [
					29 01 00 00 00 00 03 9F A5 A5		/* TEST KEY1 Enable */
					29 00 00 00 00 00 03 F0 5A 5A	/* TEST KEY2 Enable */

					29 00 00 00 00 00 03 B0 39 F4		/* Vaint SET(-4.2V) */
					29 00 00 00 00 00 08 F4 80 80 80 80 80 80 80 /* 0x80 :   -4.2V */
					29 00 00 00 00 00 03 B0 47 F4
					29 00 00 00 00 00 08 F4 80 80 80 80 80 80 80 /* 0x80 :   -4.2V */

					05 00 00 00 00 00 01 28				/* Display off */

					05 01 00 00 0A 00 01 10				/* wait 10ms(0x0A) */

					29 00 00 00 00 00 03 B0 0A CB	/* Signal DC Value Setting */
					29 00 00 00 00 00 02 CB 4F
					29 00 00 00 00 00 02 F7 0F

					29 00 00 00 00 00 03 B0 04 F2	/* Oscillator off  & wait 120ms */
					29 00 00 00 00 00 02 F2 02
					29 00 00 00 00 00 02 F7 0F

					29 00 00 00 00 00 03 B0 07 EF	/* power off & change GPO */
					29 00 00 00 00 00 02 EF 55
					29 00 00 00 00 00 02 F7 0F

					29 01 00 00 78 00 03 F0 A5 A5	/* TEST KEY2 Enable */
					29 01 00 00 00 00 03 9F 5A 5A		/* TEST KEY1 disable */
				];

				qcom,mdss-dsi-on-command-state = "dsi_lp_mode"; /* TBD */
				qcom,mdss-dsi-off-command-state = "dsi_hs_mode";

				qcom,partial-update-enabled = "single_roi";
				qcom,panel-roi-alignment=<1104 34 1104 34 1104 34>;
				qcom,compression-mode = "dsc";
				qcom,lm-split = <1104 1104>;
				qcom,mdss-dsc-encoders = <2>;
				qcom,mdss-dsc-slice-height = <34>;
				qcom,mdss-dsc-slice-width = <1104>;
				qcom,mdss-dsc-slice-per-pkt = <1>;
				qcom,mdss-dsc-bit-per-component = <8>;
				qcom,mdss-dsc-bit-per-pixel = <8>;
				qcom,mdss-dsc-block-prediction-enable;
			};
			qxga60hs {
				qcom,display-topology = <2 2 1>;
				qcom,default-topology-index = <0>;
				qcom,mdss-dsi-timing-default;

				qcom,mdss-dsi-panel-width = <2208>;
				qcom,mdss-dsi-panel-height = <1768>;

				qcom,mdss-dsi-h-pulse-width = <56>;
				qcom,mdss-dsi-h-back-porch = <60>;
				qcom,mdss-dsi-h-front-porch = <60>;
				qcom,mdss-dsi-h-sync-skew = <0>;

				qcom,mdss-dsi-v-pulse-width = <56>;
				qcom,mdss-dsi-v-back-porch = <60>;
				qcom,mdss-dsi-v-front-porch = <54>;

				qcom,mdss-mdp-transfer-time-us = <7533>;

				samsung,mdss-dsi-sot-hs-mode;
				qcom,mdss-dsi-panel-framerate = <60>;

				qcom,mdss-dsi-panel-clockrate = <1362000000>; /* 1362Mhz*/

				qcom,mdss-dsi-panel-phy-timings = [00 2C 0C 0C 29 26 0C 0C 08 03 04 00 24 1B];	/* SM8250 : dsi_phy_v4_0 */

				qcom,mdss-dsi-t-clk-pre = <0x24>;
				qcom,mdss-dsi-t-clk-post = <0x1B>;

				qcom,mdss-dsi-timing-switch-command = [ 
					29 00 00 00 00 00 03 F0 5A 5A		/* TEST KEY2 Enable */
					29 00 00 00 00 00 05 F2 41 14 BA 40		/* HS */
					29 00 00 00 00 00 03 60 08 01			/* 60Hz_HS */
					29 00 00 00 00 00 03 B0 05 F2
					29 00 00 00 00 00 03 F2 00 08			/* VFP_return */
					29 00 00 00 00 00 03 B0 0C F2
					29 00 00 00 00 00 03 F2 00 08			/* VFP_return */
					29 00 00 00 00 00 03 B0 43 B1
					29 00 00 00 00 00 19 B1					/* Common_AOR */
							07 00 07 00 07 00 07 00
							07 00 07 00 07 00 07 00
							07 00 07 00 06 DC 01 20
					29 00 00 00 00 00 02 F7 0F				/* Update key */
					29 01 00 00 00 00 03 F0 A5 A5		/* TEST KEY2 Disable */
				]; 

				qcom,mdss-dsi-on-command = [
					29 00 00 00 00 00 03 F0 5A 5A	/* TEST KEY2 Enable */

					/* **** INTERFACE SETTING **** */

					07 00 00 00 00 00 01 01			/* DSC enable :  Compression Mode*/

					/* W/A: transmit dummy 2C command before sleep out. (requested by dlab)
					 * In display off -> AOD on sequence, self display features allows
					 * 4C cmd transmission without 2C cmd, and it causes sand strom image due to HAC DDI HW chip...
					 * To prevent the issue, transmit dummy 2C command before sleep out command.
					 */
					29 00 00 00 00 00 04 2C 00 00 00

					/* **** SLEEP OUT **** */
					05 01 00 00 78 00 01 11		/* Sleep out, wait 120ms */

					/* **** SIGNAL DC VALUE SETTING **** */
					29 00 00 00 00 00 03 B0 0A CB	/* Signal DC Value Setting & wait 120ms */
					29 00 00 00 00 00 02 CB 0F
					29 01 00 00 00 00 02 F7 0F

					/* **** COMMON SETTING **** */

					29 00 00 00 00 00 02 35 00		/* TE Vsync On */

					29 00 00 00 00 00 03 ED 04 40	/* ERR_FG Setting */

					29 00 00 00 00 00 02 9B 00		/* enable UDC */

					29 00 00 00 00 00 0D B9 11 06 E5 06 FB 00 00 00 00 11 01 03		/* TSP SYNC Enable */

					29 00 00 00 00 00 18 BD											/*  LFD Setting */
						01 00 00 80 00 02 40 00 01 70 00 00 00 0B 00 00
						00 00 00 00 02 00 14

					/* **** Freq. Mode Change Setting **** */
					29 00 00 00 00 00 05 F2 41 14 BA 40		/* 60Hz_HS */
					29 00 00 00 00 00 03 60 08 01			/* 60Hz_HS */ 

					/* **** VFP & AOR setting **** */
					29 00 00 00 00 00 03 B0 05 F2
					29 00 00 00 00 00 03 F2 00 08			/* VFP_return */
					29 00 00 00 00 00 03 B0 0C F2
					29 00 00 00 00 00 03 F2 00 08			/* VFP_return */
					29 00 00 00 00 00 03 B0 43 B1
					29 00 00 00 00 00 19 B1					/* Common_AOR */
							07 00 07 00 07 00 07 00
							07 00 07 00 07 00 07 00
							07 00 07 00 06 DC 01 20
					29 00 00 00 00 00 02 F7 0F				/* Update key */

					/* **** Smooth Dimming Setting **** */
					29 00 00 00 00 00 03 B0 0B B1
					29 00 00 00 00 00 02 B1 08
					29 00 00 00 00 00 02 F7 0F				/* Update key */

					/* **** DIA Setting **** */
					29 00 00 00 00 00 03 B0 9D 64
					29 00 00 00 00 00 02 64 09

					/* **** BRIGHTNESS SETTING **** */

					29 00 00 00 00 00 03 FC 5A 5A
					29 00 00 00 00 00 02 53 20				/* WRCTRLD */
					29 00 00 00 00 00 03 51 03 FF			/* WRDISBV 450 nit */
					29 00 00 00 00 00 02 F7 0F				/* Update key */
					29 00 00 00 00 00 03 FC A5 A5

					29 01 00 00 00 00 03 F0 A5 A5	/* TEST KEY2 Disable */
				];

				qcom,mdss-dsi-off-command = [
					29 01 00 00 00 00 03 9F A5 A5		/* TEST KEY1 Enable */
					29 00 00 00 00 00 03 F0 5A 5A	/* TEST KEY2 Enable */

					29 00 00 00 00 00 03 B0 39 F4		/* Vaint SET(-4.2V) */
					29 00 00 00 00 00 08 F4 80 80 80 80 80 80 80 /* 0x80 :   -4.2V */
					29 00 00 00 00 00 03 B0 47 F4
					29 00 00 00 00 00 08 F4 80 80 80 80 80 80 80 /* 0x80 :   -4.2V */

					05 00 00 00 00 00 01 28				/* Display off */

					05 01 00 00 0A 00 01 10				/* wait 10ms(0x0A) */

					29 00 00 00 00 00 03 B0 0A CB	/* Signal DC Value Setting */
					29 00 00 00 00 00 02 CB 4F
					29 00 00 00 00 00 02 F7 0F

					29 00 00 00 00 00 03 B0 04 F2	/* Oscillator off  & wait 120ms */
					29 00 00 00 00 00 02 F2 02
					29 00 00 00 00 00 02 F7 0F

					29 00 00 00 00 00 03 B0 07 EF	/* power off & change GPO */
					29 00 00 00 00 00 02 EF 55
					29 00 00 00 00 00 02 F7 0F

					29 01 00 00 78 00 03 F0 A5 A5	/* TEST KEY2 Enable */
					29 01 00 00 00 00 03 9F 5A 5A		/* TEST KEY1 disable */
				];

				qcom,mdss-dsi-on-command-state = "dsi_lp_mode"; /* TBD */
				qcom,mdss-dsi-off-command-state = "dsi_hs_mode";

				qcom,partial-update-enabled = "single_roi";
				qcom,panel-roi-alignment=<1104 34 1104 34 1104 34>;
				qcom,compression-mode = "dsc";
				qcom,lm-split = <1104 1104>;
				qcom,mdss-dsc-encoders = <2>;
				qcom,mdss-dsc-slice-height = <34>;
				qcom,mdss-dsc-slice-width = <1104>;
				qcom,mdss-dsc-slice-per-pkt = <1>;
				qcom,mdss-dsc-bit-per-component = <8>;
				qcom,mdss-dsc-bit-per-pixel = <8>;
				qcom,mdss-dsc-block-prediction-enable;
			};
			qxga48hs {
				qcom,display-topology = <2 2 1>;
				qcom,default-topology-index = <0>;

				qcom,mdss-dsi-panel-width = <2208>;
				qcom,mdss-dsi-panel-height = <1768>;

				qcom,mdss-dsi-h-pulse-width = <56>;
				qcom,mdss-dsi-h-back-porch = <60>;
				qcom,mdss-dsi-h-front-porch = <60>;
				qcom,mdss-dsi-h-sync-skew = <0>;

				qcom,mdss-dsi-v-pulse-width = <56>;
				qcom,mdss-dsi-v-back-porch = <60>;
				qcom,mdss-dsi-v-front-porch = <60>;

				qcom,mdss-mdp-transfer-time-us = <7533>;

				samsung,mdss-dsi-sot-hs-mode;
				qcom,mdss-dsi-panel-framerate = <48>;

				qcom,mdss-dsi-panel-clockrate = <1362000000>; /* 1362Mhz*/

				qcom,mdss-dsi-panel-phy-timings = [00 2C 0C 0C 29 26 0C 0C 08 03 04 00 24 1B];	/* SM8250 : dsi_phy_v4_0 */

				qcom,mdss-dsi-t-clk-pre = <0x24>;
				qcom,mdss-dsi-t-clk-post = <0x1B>;

				qcom,mdss-dsi-timing-switch-command = [ 
					29 00 00 00 00 00 03 F0 5A 5A		/* TEST KEY2 Enable */
					29 00 00 00 00 00 05 F2 41 14 BA 40		/* HS */
					29 00 00 00 00 00 03 60 08 01			/* 60Hz_HS */
					29 00 00 00 00 00 03 B0 0C F2
					29 00 00 00 00 00 03 F2 01 CC			/* 48Hz_VFP */
					29 00 00 00 00 00 03 B0 43 B1
					29 00 00 00 00 00 19 B1					/* 48Hz_AOR */
							08 C4 08 C4 08 C4 08 C4
							08 C4 08 C4 08 C4 08 C4
							08 C4 08 C4 08 97 01 69
					29 00 00 00 00 00 02 F7 0F
					29 01 00 00 00 00 03 F0 A5 A5		/* TEST KEY2 Disable */
				]; 

				qcom,mdss-dsi-on-command = [
					29 00 00 00 00 00 03 F0 5A 5A	/* TEST KEY2 Enable */

					/* **** INTERFACE SETTING **** */

					07 00 00 00 00 00 01 01			/* DSC enable :  Compression Mode*/

					/* W/A: transmit dummy 2C command before sleep out. (requested by dlab)
					 * In display off -> AOD on sequence, self display features allows
					 * 4C cmd transmission without 2C cmd, and it causes sand strom image due to HAC DDI HW chip...
					 * To prevent the issue, transmit dummy 2C command before sleep out command.
					 */
					29 00 00 00 00 00 04 2C 00 00 00

					/* **** SLEEP OUT **** */
					05 01 00 00 78 00 01 11		/* Sleep out, wait 120ms */

					/* **** SIGNAL DC VALUE SETTING **** */
					29 00 00 00 00 00 03 B0 0A CB	/* Signal DC Value Setting & wait 120ms */
					29 00 00 00 00 00 02 CB 0F
					29 01 00 00 00 00 02 F7 0F

					/* **** COMMON SETTING **** */

					29 00 00 00 00 00 02 35 00		/* TE Vsync On */

					29 00 00 00 00 00 03 ED 04 40	/* ERR_FG Setting */

					29 00 00 00 00 00 02 9B 00		/* enable UDC */

					29 00 00 00 00 00 0D B9 11 06 E5 06 FB 00 00 00 00 11 01 03		/* TSP SYNC Enable */

					29 00 00 00 00 00 18 BD											/*  LFD Setting */
						01 00 00 80 00 02 40 00 01 70 00 00 00 0B 00 00
						00 00 00 00 02 00 14

					/* **** Freq. Mode Change Setting **** */
					29 00 00 00 00 00 05 F2 41 14 BA 40		/* 60Hz_HS */
					29 00 00 00 00 00 03 60 08 01			/* 60Hz_HS */

					/* **** VFP & AOR setting **** */
					29 00 00 00 00 00 03 B0 0C F2
					29 00 00 00 00 00 03 F2 01 CC			/* 48Hz_VFP */
					29 00 00 00 00 00 03 B0 43 B1
					29 00 00 00 00 00 19 B1					/* 48Hz_AOR */
							08 C4 08 C4 08 C4 08 C4
							08 C4 08 C4 08 C4 08 C4
							08 C4 08 C4 08 97 01 69
					29 00 00 00 00 00 02 F7 0F				/* Update key */

					/* **** Smooth Dimming Setting **** */
					29 00 00 00 00 00 03 B0 0B B1
					29 00 00 00 00 00 02 B1 08
					29 00 00 00 00 00 02 F7 0F				/* Update key */

					/* **** DIA Setting **** */
					29 00 00 00 00 00 03 B0 9D 64
					29 00 00 00 00 00 02 64 09

					/* **** BRIGHTNESS SETTING **** */

					29 00 00 00 00 00 03 FC 5A 5A
					29 00 00 00 00 00 02 53 20				/* WRCTRLD */
					29 00 00 00 00 00 03 51 03 FF			/* WRDISBV 450 nit */
					29 00 00 00 00 00 02 F7 0F				/* Update key */
					29 00 00 00 00 00 03 FC A5 A5

					29 01 00 00 00 00 03 F0 A5 A5	/* TEST KEY2 Disable */
				];

				qcom,mdss-dsi-off-command = [
					29 01 00 00 00 00 03 9F A5 A5		/* TEST KEY1 Enable */
					29 00 00 00 00 00 03 F0 5A 5A	/* TEST KEY2 Enable */

					29 00 00 00 00 00 03 B0 39 F4		/* Vaint SET(-4.2V) */
					29 00 00 00 00 00 08 F4 80 80 80 80 80 80 80 /* 0x80 :   -4.2V */
					29 00 00 00 00 00 03 B0 47 F4
					29 00 00 00 00 00 08 F4 80 80 80 80 80 80 80 /* 0x80 :   -4.2V */

					05 00 00 00 00 00 01 28				/* Display off */

					05 01 00 00 0A 00 01 10				/* wait 10ms(0x0A) */

					29 00 00 00 00 00 03 B0 0A CB	/* Signal DC Value Setting */
					29 00 00 00 00 00 02 CB 4F
					29 00 00 00 00 00 02 F7 0F

					29 00 00 00 00 00 03 B0 04 F2	/* Oscillator off  & wait 120ms */
					29 00 00 00 00 00 02 F2 02
					29 00 00 00 00 00 02 F7 0F

					29 00 00 00 00 00 03 B0 07 EF	/* power off & change GPO */
					29 00 00 00 00 00 02 EF 55
					29 00 00 00 00 00 02 F7 0F

					29 01 00 00 78 00 03 F0 A5 A5	/* TEST KEY2 Enable */
					29 01 00 00 00 00 03 9F 5A 5A		/* TEST KEY1 disable */
				];

				qcom,mdss-dsi-on-command-state = "dsi_lp_mode"; /* TBD */
				qcom,mdss-dsi-off-command-state = "dsi_hs_mode";

				qcom,partial-update-enabled = "single_roi";
				qcom,panel-roi-alignment=<1104 34 1104 34 1104 34>;
				qcom,compression-mode = "dsc";
				qcom,lm-split = <1104 1104>;
				qcom,mdss-dsc-encoders = <2>;
				qcom,mdss-dsc-slice-height = <34>;
				qcom,mdss-dsc-slice-width = <1104>;
				qcom,mdss-dsc-slice-per-pkt = <1>;
				qcom,mdss-dsc-bit-per-component = <8>;
				qcom,mdss-dsc-bit-per-pixel = <8>;
				qcom,mdss-dsc-block-prediction-enable;
			};
		};
	};
};
